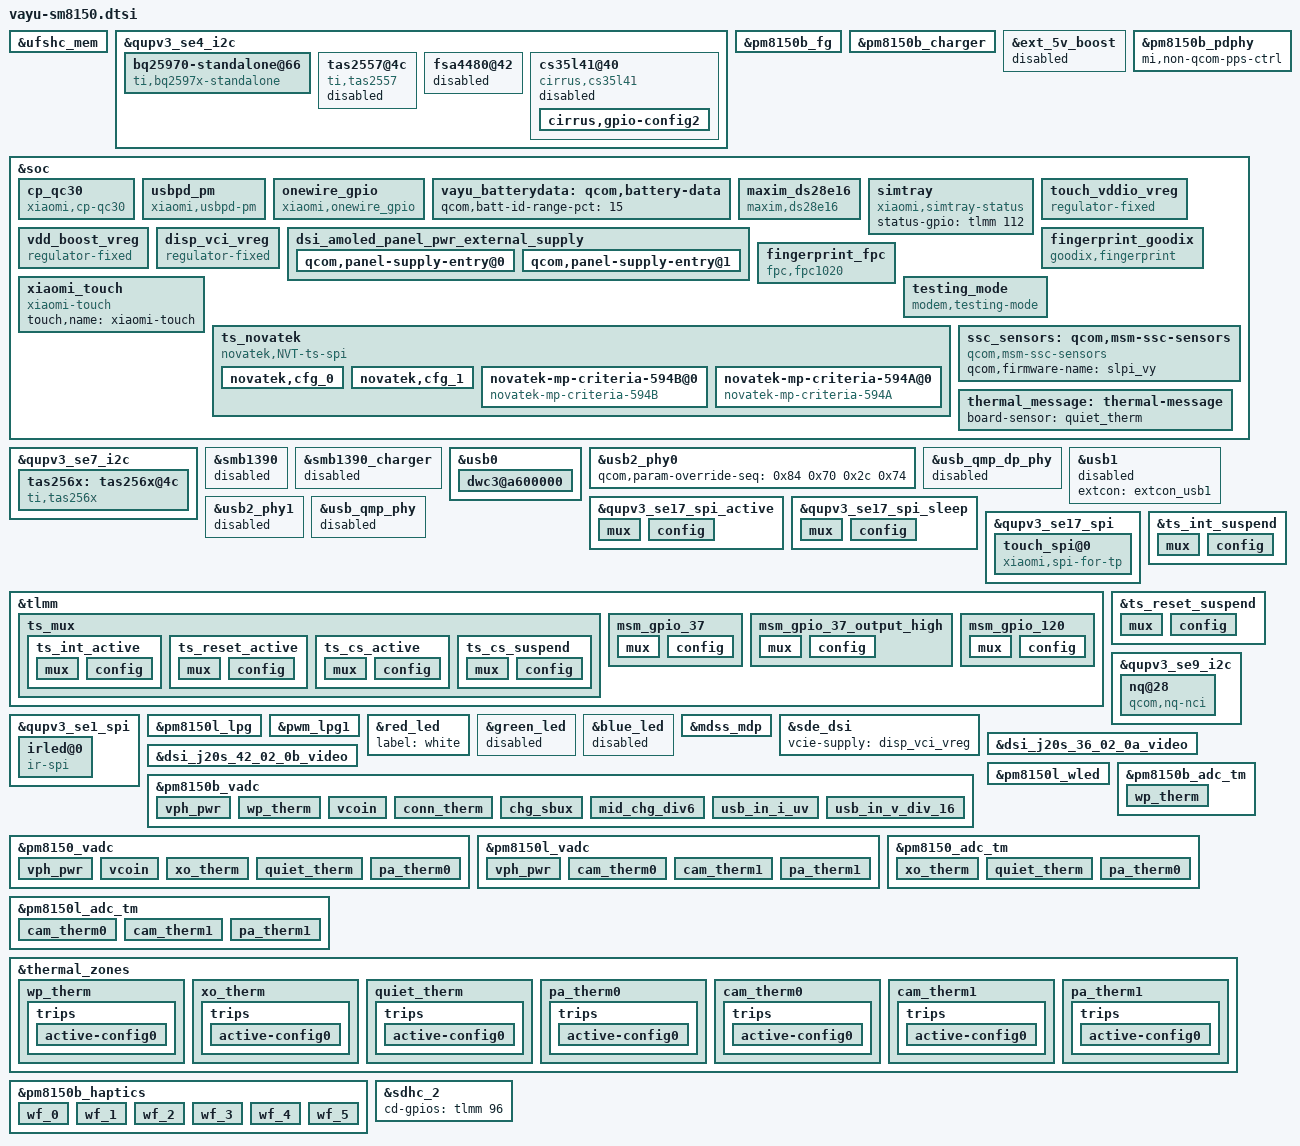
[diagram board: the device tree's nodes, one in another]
/*
this file is for attribution only of vayu
And public attribution of xiaomi platforms(like J20S and so and)
*/
#include "vayu-pinctrl.dtsi"
#include "xiaomi-sm8150-common.dtsi"
#include "vayu-sm8150-camera-sensor-mtp.dtsi"

&ufshc_mem {
	vcc-voltage-level = <2504000 2950000>;
	vcc-low-voltage-sup;
	qcom,vccq-parent-supply = <&pm8150l_s8>;
	qcom,vccq-parent-max-microamp = <210000>;
	vccq-supply = <&pm8150_l9>;
	vccq-max-microamp = <700000>;
};

&qupv3_se4_i2c {
#include "smb1390.dtsi"
};



&pm8150b_fg {
	qcom,battery-data = <&vayu_batterydata>;
	qcom,rapid-soc-dec-en;
	qcom,soc-scale-mode-en;
	qcom,five-pin-battery;
	qcom,soc-hi-res;
	qcom,soc_decimal_rate = <
		0  38
		10 35
		20 33
		30 33
		40 33
		50 33
		60 33
		70 30
		80 25
		90 20
		95 10 >;
	qcom,ki-coeff-low-chg = <315>;
	qcom,ki-coeff-med-chg = <183>;
	qcom,fg-sys-term-current = <(-300)>;
	qcom,fg-ffc-sys-term-current = <(-1160)>;
	qcom,fg-cutoff-voltage = <3400>;
	qcom,fg-cutoff-current = <200>;
	qcom,fg-empty-voltage = <3100>;
	qcom,soc-scale-vbatt-mv = <3600>;
	qcom,fg-batt-temp-delta = <6>;
	qcom,fg-force-load-profile;
	qcom,shutdown-delay-enable;
	/* ESR fast calibration */
	qcom,fg-esr-timer-chg-fast = <0 7>;
	qcom,fg-esr-timer-dischg-fast = <0 7>;
	qcom,fg-esr-timer-chg-slow = <0 96>;
	qcom,fg-esr-timer-dischg-slow = <0 96>;
	qcom,fg-esr-cal-soc-thresh = <26 230>;
	qcom,fg-esr-cal-temp-thresh = <10 40>;
	qcom,ki-coeff-chg-med-hi-thresh-ma = <1000>;
	qcom,ki-coeff-chg-low-med-thresh-ma = <500>;
	qcom,ffc-ki-coeff-chg-med-hi-thresh-ma = <3900>;
	qcom,ffc-ki-coeff-chg-low-med-thresh-ma = <3500>;
};

&pm8150b_charger {
	qcom,sec-charger-config = <0>;
	qcom,usb-icl-ua = <3000000>;
	qcom,fcc-max-ua = <5900000>;
	qcom,fv-max-uv = <4475000>;
	qcom,non-fcc-fv-max-uv = <4450000>;
	//qcom,chg-warm-th= <450>;
	//qcom,chg-cool-th= <150>;
	qcom,auto-recharge-soc = <99>;
	qcom,chg-term-src = <1>;
	qcom,chg-term-current-ma = <(-200)>;
	mi,use-bq-pump;
	qcom,usbpd-phandle = <&pm8150b_pdphy>;
	qcom,battery-data = <&vayu_batterydata>;
	//mi,six-pin-step-chg-params = <4250000  6000000
	//			4450000  5400000
	//			4480000  4000000>;
	//mi,six-pin-step-chg;
	//mi,six-pin-soc-th = <45>;
	mi,fcc-batt-unverify-ua = <2000000>;
	mi,support-ffc;
	qcom,disable-suspend-on-collapse;
	qcom,thermal-mitigation = <3000000 2800000 2600000 2400000 2200000 2100000 2000000
				   1800000 1600000 1500000 1400000 1200000 1000000 900000
				   800000 500000>;
	qcom,thermal-mitigation-icl
				= <2800000 2700000 2600000 2400000 2200000 2100000 2000000
				   2000000 2000000 2000000 2000000 2000000 2000000 2000000
				   2000000 2000000>;
	qcom,thermal-mitigation-dcp
				= <1800000 1800000 1800000 1800000 1800000 1800000 1800000
				   1800000 1800000 1700000 1600000 1400000 1200000 1100000
				   1100000 1000000>;
	qcom,thermal-mitigation-qc2
				= <1500000 1500000 1500000 1500000 1450000 1400000 1350000
				   1300000 1150000 1100000 1000000 900000 850000 750000
				   650000 500000>;
	qcom,thermal-fcc-qc3-normal
				= <3200000 3000000 2800000 2600000 2500000 2400000 2300000
				   2200000 2100000 1800000 1600000 1400000 1200000 1000000
				   750000 750000>;
	qcom,thermal-fcc-qc3-cp
				= <3600000 3600000 3600000 3600000 3200000 3200000 3200000
				   3200000 3100000 2800000 2400000 2200000 2000000 1300000
				   750000 300000>;
	qcom,thermal-fcc-qc3-classb-cp
				= <4800000 4700000 4600000 4500000 4400000 4200000 4200000
				   4200000 4000000 3600000 3400000 3200000 3000000 2200000
				   1000000 300000>;
	qcom,thermal-mitigation-pd-base
				= <3000000 2800000 2600000 2500000 2500000 2500000 2500000
				   2500000 2500000 2400000 2200000 2000000 1600000 1300000
				   1000000 500000>;
	qcom,thermal-fcc-pps-cp
				= <4800000 4700000 4600000 4500000 4400000 4200000 4200000
				   4200000 4000000 3600000 3400000 3200000 3000000 2200000
				   1000000 300000>;
	qcom,thermal-fcc-pps-bq
				= <6000000 5700000 5475000 5250000 5025000 4800000 4575000
				   4350000 4100000 3500000 3000000 2400000 2000000 1500000
				   1000000 500000>;
	qcom,thermal-fcc-qc3-cp
				= <4800000 4600000 4400000 4200000 4000000 3800000 3600000
				   3400000 3000000 2600000 2400000 2200000 2000000 1300000
				   1000000 300000>;
	qcom,thermal-fcc-qc3-classb-cp
				= <5100000 4700000 4300000 4000000 3600000 3500000 3400000
				   3400000 3400000 3200000 2500000 2200000 2000000 1300000
				   1000000 300000>;
	qcom,thermal-mitigation-pd-base
				= <3000000 2800000 2600000 2400000 2200000 2000000 1800000
				   1600000 1600000 1400000 1200000 1100000 1050000 1000000
				   950000 500000>;
	qcom,thermal-mitigation-voice
				= <6000000 2200000 2200000 1000000 1000000 800000  800000
				   800000  800000  700000  700000  600000  600000  600000
				   500000  400000>;


	io-channels = <&pm8150b_vadc ADC_MID_CHG_DIV6>,
		      <&pm8150b_vadc ADC_USB_IN_V_16>,
		      <&pm8150b_vadc ADC_USB_IN_I>,
		      <&pm8150b_vadc ADC_SBUx>,
		      <&pm8150b_vadc ADC_VPH_PWR>,
		      <&pm8150b_vadc ADC_CHG_TEMP>;
	io-channel-names = "mid_voltage",
			   "usb_in_voltage",
			   "usb_in_current",
			   "sbux_res",
			   "vph_voltage",
			   "chg_temp";
//	qcom,battery-data = <&mtp_batterydata>;
	dpdm-supply = <&usb2_phy0>;
	qcom,distinguish-qc-class-ab;
	qcom,lpd-disable;
	qcom,sw-jeita-enable;
	qcom,step-charging-enable;
	qcom,wd-bark-time-secs = <16>;
};

&ext_5v_boost {
	status = "disable";
};

&pm8150b_pdphy {
	mi,non-qcom-pps-ctrl;
};

&qupv3_se4_i2c {
	#address-cells = <1>;
	#size-cells = <0>;
	status = "ok";
	bq25970-standalone@66 {
		compatible = "ti,bq2597x-standalone";
		reg = <0x66>;
		interrupt-parent = <&tlmm>;
		interrupts = <10 0x2002>;
		pinctrl-names = "default";
		pinctrl-0 = <&bq2597x_master_int_default &bq2597x_master_int_suspend>;

		/*ti,bq2597x,bat-ovp-disable;*/
		ti,bq2597x,bat-ovp-alarm-disable;
		ti,bq2597x,bat-ocp-disable;
		ti,bq2597x,bat-ocp-alarm-disable;
		ti,bq2597x,bat-ucp-alarm-disable;
		ti,bq2597x,bat-ucp-disable;

		/*ti,bq2597x,bus-ovp-alarm-disable;
		ti,bq2597x,bus-ocp-disable;
		ti,bq2597x,bus-ocp-alarm-disable;*/
		ti,bq2597x,bat-therm-disable;
		ti,bq2597x,bus-therm-disable;
		ti,bq2597x,die-therm-disable;

		ti,bq2597x,bat-ovp-threshold = <4550>;
		ti,bq2597x,bat-ovp-alarm-threshold = <4525>;
		//ti,bq2597x,bat-ocp-threshold = <8000>;
		//ti,bq2597x,bat-ocp-alarm-threshold = <7500>;

		ti,bq2597x,bus-ovp-threshold = <12000>;
		ti,bq2597x,bus-ovp-alarm-threshold = <11000>;
		ti,bq2597x,bus-ocp-threshold = <3750>;
		ti,bq2597x,bus-ocp-alarm-threshold = <3500>;

		//ti,bq2597x,bat-ucp-alarm-threshold = <2000>;

		ti,bq2597x,bat-therm-threshold = <0x15>;/*4.1%*/
		ti,bq2597x,bus-therm-threshold = <0x15>;/*4.1%*/
		ti,bq2597x,die-therm-threshold = <145>;

		ti,bq2597x,ac-ovp-threshold = <14>;
		//ti,bq2597x,sense-resistor-mohm = <2>;

	};
};

&soc {
	cp_qc30 {
		compatible = "xiaomi,cp-qc30";
		status = "ok";
		mi,qc3-bat-volt-max = <4420>;
		mi,qc3-bat-curr-max = <3600>;
		mi,qc3-bus-volt-max = <12000>;
		mi,qc3-bus-curr-max = <2100>;
		mi,qc3-battery-warm-th = <450>;
		mi,use-qcom-gauge;
		//mi,cp-sec-enable;
	};

	usbpd_pm {
		compatible = "xiaomi,usbpd-pm";
		status = "ok";
		mi,pd-bat-volt-max = <4500>;
		mi,pd-ffc-bat-volt-max = <4480>;
		mi,pd-bat-curr-max = <6000>;
		mi,pd-bus-volt-max = <12000>;
		mi,pd-bus-curr-max = <3000>;
		mi,pd-non-ffc-bat-volt-max = <4450>;
		mi,pd-bus-curr-compensate  = <0>;
		mi,pd-battery-warm-th = <450>;
		mi,use-qcom-gauge;
		//mi,cp-sec-enable;
	};

	onewire_gpio: onewire_gpio {
		compatible = "xiaomi,onewire_gpio";
		label = "xm_onewire";
		xiaomi,version = <1>;
		xiaomi,ow_gpio = <&tlmm 21 0x00>;
		mi,onewire-gpio-cfg-addr = <0x03515000 0x4>;
		xiaomi,gpio_number = <21>;
		pinctrl-names = "onewire_active", "onewire_sleep";
		pinctrl-0 = <&onewire_gpio_active>;
		pinctrl-1 = <&onewire_gpio_sleep>;
		status = "ok";
	};
	vayu_batterydata: qcom,battery-data {
		qcom,batt-id-range-pct = <15>;
		#include "fg-gen4-batterydata-vayu-NVT-5160mah.dtsi"
		#include "fg-gen4-batterydata-vayu-sunwoda-5160mah.dtsi"
	};

	maxim_ds28e16: maxim_ds28e16 {
		compatible = "maxim,ds28e16";
		label = "max_ds28e16";
		maxim,version = <1>;
		status = "ok";
	};

        simtray {
                compatible = "xiaomi,simtray-status";
                status-gpio = <&tlmm 112 0x00>;
        };
};

&qupv3_se4_i2c {
	status = "ok";
	tas2557@4c {
		status = "disabled";
		compatible = "ti,tas2557";
		reg = <0x4c>;
		//ti,cdc-reset-gpio = <&tlmm 59 0>;
		ti,irq-gpio = <&tlmm 60 0>;
		ti,i2s-bits = <16>;
		ti,bypass-tmax = <0>;
	};

	fsa4480@42 {
		status = "disabled";
	};

	cs35l41@40 {
		status = "disabled";
		#sound-dai-cells = <1>;
		compatible = "cirrus,cs35l41";
		cs,cdc-reset-gpio = <&tlmm 89 0x01>;
		reg = <0x40>;
		pinctrl-names = "cs35l41_irq_default";
		pinctrl-0 = <&cs35l41_int_default>;
		interrupt-parent = <&tlmm>;
		interrupts = <10 8>;

		cirrus,temp-warn_threshold = <3>;
		cirrus,boost-peak-milliamp = <4000>;
		cirrus,boost-ind-nanohenry = <1000>;
		cirrus,boost-cap-microfarad = <15>;
		cirrus,gpio-config2 {
			cirrus,gpio-src-select = <0x4>;
			cirrus,gpio-output-enable;
		};
/*
		VA-supply = <&dummy_vreg>;
		VP-supply = <&dummy_vreg>;
		interrupt-parent = <&tlmm>;
		interrupts = <11 8>;
		reset-gpios = <&tlmm 7 0x01>;
		VA-supply = <&pm8998_s4>;
		VP-supply = <&audio_vsys>;
		cirrus,boost-peak-milliamp = <4500>;
		cirrus,boost-ind-nanohenry = <1000>;
		cirrus,boost-cap-microfarad = <15>;
		cirrus,gpio-config2 {
			cirrus,gpio-src-select = <0x4>;
			cirrus,gpio-output-enable;
		};
*/
	};
};

&qupv3_se7_i2c {
	status = "ok";
	tas256x:tas256x@4c {
		#sound-dai-cells = <0>;
		compatible = "ti,tas256x";/*or "ti,tas2564" or "ti,tas256x" */
		reg = <0x4c>;//register tas256x_i2c_driver
		ti,left-channel = <0x4d>;  //receiver address
		ti,right-channel = <0x4c>; //speaker address
		ti,channels = <2>; /* channel number */
		ti,reset-gpio = <&tlmm 89 0>;  //SPKR_RST1
		ti,reset-gpio2 = <&tlmm 92 0>;  //SPKR_RST2
		pinctrl-names = "default";
		//pinctrl-0 = <&reset_stat_default>;
		//ti,reset-gpio = <&pm6150l_gpios 8 GPIO_ACTIVE_LOW>;
		ti,irq-gpio = <&tlmm 90 0>;//spkr_int1 left
		ti,irq-gpio2 = <&tlmm 91 0>;//spkr_int2 right
		status = "ok";
		ti,iv-width = <16>;
		ti,vbat-mon = <0>;
	};
};

&smb1390 {
	status = "disabled";
};

&smb1390_charger {
	status = "disabled";
};

&usb0 {
	dwc3@a600000 {
		usb-phy = <&usb2_phy0>, <&usb_nop_phy>;
		maximum-speed = "high-speed";
	};
};

&usb2_phy0 {
	qcom,param-override-seq =
		<0x84 0x70
		 0x2c 0x74>;
};

&usb_qmp_dp_phy {
	status = "disabled";
};

&usb1 {
	extcon = <&extcon_usb1>;
        status = "disabled";
};

&usb2_phy1 {
        status = "disabled";
};

&usb_qmp_phy {
        status = "disabled";
};

&soc {
	touch_vddio_vreg: touch_vddio_vreg {
		compatible = "regulator-fixed";
		regulator-name = "disp_vddio_vreg";
		startup-delay-us = <4000>;
		enable-active-high;
		regulator-boot-on;
		gpio = <&tlmm 100 0>;
	 };

	vdd_boost_vreg: vdd_boost_vreg {
		compatible = "regulator-fixed";
		regulator-name = "vdd_boost_vreg";
		startup-delay-us = <4000>;
		enable-active-high;
		regulator-always-on;
		gpio = <&pm8150b_gpios 5 0>;
	 };

	disp_vci_vreg: disp_vci_vreg {
		compatible = "regulator-fixed";
		regulator-name = "disp_vci_vreg";
		start-delay-us = <4000>;
		enable-active-high;
		regulator-boot-on;
		gpio = <&tlmm 21 0>;
	};

	dsi_amoled_panel_pwr_external_supply: dsi_amoled_panel_pwr_external_supply {
		#address-cells = <1>;
		#size-cells = <0>;

		qcom,panel-supply-entry@0 {
			reg = <0>;
			qcom,supply-name = "vddio";
			qcom,supply-min-voltage = <1800000>;
			qcom,supply-max-voltage = <1800000>;
			qcom,supply-enable-load = <62000>;
			qcom,supply-disable-load = <80>;
			//qcom,supply-post-on-sleep = <20>;
		};

		qcom,panel-supply-entry@1 {
			reg = <1>;
			qcom,supply-name = "vcie";
			qcom,supply-min-voltage = <3000000>;
			qcom,supply-max-voltage = <3000000>;
			qcom,supply-enable-load = <62000>;
			qcom,supply-disable-load = <80>;
			qcom,supply-post-on-sleep = <10>;
			qcom,supply-pre-off-sleep = <10>;
		};
	};

	fingerprint_goodix {
		compatible = "goodix,fingerprint";
		goodix,gpio-reset = <&tlmm 37 0x0>;
		goodix,gpio-irq = <&tlmm 120 0x0>;
		//goodix.gpio_pwr = <&tlmm 125 0x0>;
		//fp_vdd_vreg = <&pm8150l_l7>;
		status = "ok";
	};


        fingerprint_fpc {
               compatible = "fpc,fpc1020";
               fpc,gpio_rst    = <&tlmm 37 0x0>;
               fpc,gpio_irq    = <&tlmm 120 0x0>;
               pinctrl-names = "fpc1020_reset_reset",
                       "fpc1020_reset_active",
                       "fpc1020_irq_active";

               pinctrl-0 = <&msm_gpio_37>;
               pinctrl-1 = <&msm_gpio_37_output_high>;
               pinctrl-2 = <&msm_gpio_120>;
               status = "ok";
       };


	xiaomi_touch {
		compatible = "xiaomi-touch";
		status = "ok";
		touch,name = "xiaomi-touch";
	};

	testing_mode {
		compatible = "modem,testing-mode";
		status-gpio = <&tlmm 81 0x00>,
                      <&tlmm 133 0x00>;
		debounce-time = <30>;
		pinctrl-names = "default";
		pinctrl-0 = <&ant_sub_ctrl_irq &ant_top_ctrl_irq>;
	};
};

/*Touch SPI state init*/
&qupv3_se17_spi_active {
		mux {
				pins = "gpio55", "gpio56", "gpio57";
				function = "qup17";
		};

		config {
				pins = "gpio55", "gpio56", "gpio57";
				drive-strength = <6>;
				// bias-disable;
				bias-pull-down;
		};
};

&qupv3_se17_spi_sleep {
		mux {
				pins = "gpio55", "gpio56", "gpio57";
				function = "gpio";
		};

		config {
				pins = "gpio55", "gpio56", "gpio57";
				drive-strength = <6>;
				bias-pull-down;
		};
};

&qupv3_se17_spi {
		pinctrl-0 = <&qupv3_se17_spi_active>;
		pinctrl-1 = <&qupv3_se17_spi_sleep>;
};

/*IC int pin, rst pin init*/
&tlmm {
	ts_mux {
		ts_int_active: ts_int_active {
			mux {
				pins = "gpio122";
				function = "gpio";
			};

			config {
				pins = "gpio122";
				drive-strength = <16>;
				bias-pull-down;
			};
		};

		ts_reset_active: ts_reset_active {
			mux {
				pins = "gpio12";
				function = "gpio";
			};

			config {
				pins = "gpio12";
				drive-strength = <16>;
				bias-pull-up;
			};
		};

		ts_cs_active: ts_cs_active {
			mux {
				pins = "gpio58";
				function = "qup17";
			};

			config {
				pins = "gpio58";
				drive-strength = <6>;
				bias-disable;
			};
		};

		ts_cs_suspend: ts_cs_suspend {
			mux {
				pins = "gpio58";
				function = "gpio";
			};

			config {
				pins = "gpio58";
				drive-strength = <6>;
				bias-pull-down;
				output-low;
			};
		};
	};
};

&ts_int_suspend {
		mux {
				pins = "gpio122";
				function = "gpio";
		};

		config {
				pins = "gpio122";
				drive-strength = <16>;
			bias-disable;
			input-enable;
		};
};

&ts_reset_suspend {
	mux {
		pins = "gpio12";
		function = "gpio";
	};

	config {
		pins = "gpio12";
		drive-strength = <16>;
		bias-disable;
	};
};

&qupv3_se17_spi {
		status = "ok";
		touch_spi@0 {
				compatible = "xiaomi,spi-for-tp";
				reg = <0>;
				status = "ok";
				spi-max-frequency = <10000000>;  //10M
		};
};

/* Novatek device tree node */
&soc {
	ts_novatek {
		compatible = "novatek,NVT-ts-spi";
		status = "ok";
		spi-max-frequency = <10000000>;  /*4800000,9600000,15000000,19200000 10M*/
		novatek,reset-gpio = <&tlmm 12 0x00>;
		novatek,irq-gpio = <&tlmm 122 0x2001>;
		pinctrl-names = "pmx_ts_active", "pmx_ts_suspend";
		pinctrl-0 = <&ts_int_active &ts_reset_active &ts_cs_active>;
		pinctrl-1 = <&ts_int_suspend &ts_reset_suspend &ts_cs_suspend>;
		/* 672 */
		/*novatek,swrst-n8-addr = <0x01F01A>;*/
		/* 672A */
		novatek,swrst-n8-addr = <0x03F0FE>;
		novatek,spi-rd-fast-addr = <0x03F310>;
		/* MP */
		novatek,mp-support-dt;
		novatek,config-array-size = <2>;
		novatek,cfg_0 {
			novatek,tp-vendor = <0x46>;
			novatek,display-maker = <0x36>;
			novatek,fw-name = "j20s_novatek_ts_fw01.bin";
			novatek,mp-name = "j20s_novatek_ts_mp01.bin";
			novatek,clicknum-file-name = "nvt+tianma";
		};
		novatek,cfg_1 {
			novatek,tp-vendor = <0x53>;
			novatek,display-maker = <0x42>;
			novatek,fw-name = "j20s_novatek_ts_fw02.bin";
			novatek,mp-name = "j20s_novatek_ts_mp02.bin";
			novatek,clicknum-file-name = "nvt+csot";
		};
		/* for Xiaomi J20S 672C CSOT6.67" module */
		novatek-mp-criteria-594B@0 {
			#address-cells = <1>;
			#size-cells = <0>;
			compatible = "novatek-mp-criteria-594B";
			/* MP Config */
			IC_X_CFG_SIZE = <18>;
			IC_Y_CFG_SIZE = <36>;
			IC_KEY_CFG_SIZE = <4>;
			X_Channel = <18>;
			Y_Channel = <36>;
			AIN_X = <0 1 2 3 4 5 6 7 8 9 10 11 12 13 14 15 16 17>;
			AIN_Y = <0 1 2 3 4 5 6 7 8 9 10 11 12 13 14 15 16 17
						18 19 20 21 22 23 24 25 26 27 28 29 30 31 32 33 34 35>;
			AIN_KEY = <0 1 2 0xFF>;
			/* MP Criteria */
			PS_Config_Lmt_Short_Rawdata_P = <
				14008 14008 14008 14008 14008 14008 14008 14008 14008 14008 14008 14008 14008 14008 14008 14008 14008 14008
				14008 14008 14008 14008 14008 14008 14008 14008 14008 14008 14008 14008 14008 14008 14008 14008 14008 14008
				14008 14008 14008 14008 14008 14008 14008 14008 14008 14008 14008 14008 14008 14008 14008 14008 14008 14008
				14008 14008 14008 14008 14008 14008 14008 14008 14008 14008 14008 14008 14008 14008 14008 14008 14008 14008
				14008 14008 14008 14008 14008 14008 14008 14008 14008 14008 14008 14008 14008 14008 14008 14008 14008 14008
				14008 14008 14008 14008 14008 14008 14008 14008 14008 14008 14008 14008 14008 14008 14008 14008 14008 14008
				14008 14008 14008 14008 14008 14008 14008 14008 14008 14008 14008 14008 14008 14008 14008 14008 14008 14008
				14008 14008 14008 14008 14008 14008 14008 14008 14008 14008 14008 14008 14008 14008 14008 14008 14008 14008
				14008 14008 14008 14008 14008 14008 14008 14008 14008 14008 14008 14008 14008 14008 14008 14008 14008 14008
				14008 14008 14008 14008 14008 14008 14008 14008 14008 14008 14008 14008 14008 14008 14008 14008 14008 14008
				14008 14008 14008 14008 14008 14008 14008 14008 14008 14008 14008 14008 14008 14008 14008 14008 14008 14008
				14008 14008 14008 14008 14008 14008 14008 14008 14008 14008 14008 14008 14008 14008 14008 14008 14008 14008
				14008 14008 14008 14008 14008 14008 14008 14008 14008 14008 14008 14008 14008 14008 14008 14008 14008 14008
				14008 14008 14008 14008 14008 14008 14008 14008 14008 14008 14008 14008 14008 14008 14008 14008 14008 14008
				14008 14008 14008 14008 14008 14008 14008 14008 14008 14008 14008 14008 14008 14008 14008 14008 14008 14008
				14008 14008 14008 14008 14008 14008 14008 14008 14008 14008 14008 14008 14008 14008 14008 14008 14008 14008
				14008 14008 14008 14008 14008 14008 14008 14008 14008 14008 14008 14008 14008 14008 14008 14008 14008 14008
				14008 14008 14008 14008 14008 14008 14008 14008 14008 14008 14008 14008 14008 14008 14008 14008 14008 14008
				14008 14008 14008 14008 14008 14008 14008 14008 14008 14008 14008 14008 14008 14008 14008 14008 14008 14008
				14008 14008 14008 14008 14008 14008 14008 14008 14008 14008 14008 14008 14008 14008 14008 14008 14008 14008
				14008 14008 14008 14008 14008 14008 14008 14008 14008 14008 14008 14008 14008 14008 14008 14008 14008 14008
				14008 14008 14008 14008 14008 14008 14008 14008 14008 14008 14008 14008 14008 14008 14008 14008 14008 14008
				14008 14008 14008 14008 14008 14008 14008 14008 14008 14008 14008 14008 14008 14008 14008 14008 14008 14008
				14008 14008 14008 14008 14008 14008 14008 14008 14008 14008 14008 14008 14008 14008 14008 14008 14008 14008
				14008 14008 14008 14008 14008 14008 14008 14008 14008 14008 14008 14008 14008 14008 14008 14008 14008 14008
				14008 14008 14008 14008 14008 14008 14008 14008 14008 14008 14008 14008 14008 14008 14008 14008 14008 14008
				14008 14008 14008 14008 14008 14008 14008 14008 14008 14008 14008 14008 14008 14008 14008 14008 14008 14008
				14008 14008 14008 14008 14008 14008 14008 14008 14008 14008 14008 14008 14008 14008 14008 14008 14008 14008
				14008 14008 14008 14008 14008 14008 14008 14008 14008 14008 14008 14008 14008 14008 14008 14008 14008 14008
				14008 14008 14008 14008 14008 14008 14008 14008 14008 14008 14008 14008 14008 14008 14008 14008 14008 14008
				14008 14008 14008 14008 14008 14008 14008 14008 14008 14008 14008 14008 14008 14008 14008 14008 14008 14008
				14008 14008 14008 14008 14008 14008 14008 14008 14008 14008 14008 14008 14008 14008 14008 14008 14008 14008
				14008 14008 14008 14008 14008 14008 14008 14008 14008 14008 14008 14008 14008 14008 14008 14008 14008 14008
				14008 14008 14008 14008 14008 14008 14008 14008 14008 14008 14008 14008 14008 14008 14008 14008 14008 14008
				14008 14008 14008 14008 14008 14008 14008 14008 14008 14008 14008 14008 14008 14008 14008 14008 14008 14008
				14008 14008 14008 14008 14008 14008 14008 14008 14008 14008 14008 14008 14008 14008 14008 14008 14008 14008
				14008 14008 14008>;

			PS_Config_Lmt_Short_Rawdata_N = <
				10000 10000 10000 10000 10000 10000 10000 10000 10000 10000 10000 10000 10000 10000 10000 10000 10000 10000
				10000 10000 10000 10000 10000 10000 10000 10000 10000 10000 10000 10000 10000 10000 10000 10000 10000 10000
				10000 10000 10000 10000 10000 10000 10000 10000 10000 10000 10000 10000 10000 10000 10000 10000 10000 10000
				10000 10000 10000 10000 10000 10000 10000 10000 10000 10000 10000 10000 10000 10000 10000 10000 10000 10000
				10000 10000 10000 10000 10000 10000 10000 10000 10000 10000 10000 10000 10000 10000 10000 10000 10000 10000
				10000 10000 10000 10000 10000 10000 10000 10000 10000 10000 10000 10000 10000 10000 10000 10000 10000 10000
				10000 10000 10000 10000 10000 10000 10000 10000 10000 10000 10000 10000 10000 10000 10000 10000 10000 10000
				10000 10000 10000 10000 10000 10000 10000 10000 10000 10000 10000 10000 10000 10000 10000 10000 10000 10000
				10000 10000 10000 10000 10000 10000 10000 10000 10000 10000 10000 10000 10000 10000 10000 10000 10000 10000
				10000 10000 10000 10000 10000 10000 10000 10000 10000 10000 10000 10000 10000 10000 10000 10000 10000 10000
				10000 10000 10000 10000 10000 10000 10000 10000 10000 10000 10000 10000 10000 10000 10000 10000 10000 10000
				10000 10000 10000 10000 10000 10000 10000 10000 10000 10000 10000 10000 10000 10000 10000 10000 10000 10000
				10000 10000 10000 10000 10000 10000 10000 10000 10000 10000 10000 10000 10000 10000 10000 10000 10000 10000
				10000 10000 10000 10000 10000 10000 10000 10000 10000 10000 10000 10000 10000 10000 10000 10000 10000 10000
				10000 10000 10000 10000 10000 10000 10000 10000 10000 10000 10000 10000 10000 10000 10000 10000 10000 10000
				10000 10000 10000 10000 10000 10000 10000 10000 10000 10000 10000 10000 10000 10000 10000 10000 10000 10000
				10000 10000 10000 10000 10000 10000 10000 10000 10000 10000 10000 10000 10000 10000 10000 10000 10000 10000
				10000 10000 10000 10000 10000 10000 10000 10000 10000 10000 10000 10000 10000 10000 10000 10000 10000 10000
				10000 10000 10000 10000 10000 10000 10000 10000 10000 10000 10000 10000 10000 10000 10000 10000 10000 10000
				10000 10000 10000 10000 10000 10000 10000 10000 10000 10000 10000 10000 10000 10000 10000 10000 10000 10000
				10000 10000 10000 10000 10000 10000 10000 10000 10000 10000 10000 10000 10000 10000 10000 10000 10000 10000
				10000 10000 10000 10000 10000 10000 10000 10000 10000 10000 10000 10000 10000 10000 10000 10000 10000 10000
				10000 10000 10000 10000 10000 10000 10000 10000 10000 10000 10000 10000 10000 10000 10000 10000 10000 10000
				10000 10000 10000 10000 10000 10000 10000 10000 10000 10000 10000 10000 10000 10000 10000 10000 10000 10000
				10000 10000 10000 10000 10000 10000 10000 10000 10000 10000 10000 10000 10000 10000 10000 10000 10000 10000
				10000 10000 10000 10000 10000 10000 10000 10000 10000 10000 10000 10000 10000 10000 10000 10000 10000 10000
				10000 10000 10000 10000 10000 10000 10000 10000 10000 10000 10000 10000 10000 10000 10000 10000 10000 10000
				10000 10000 10000 10000 10000 10000 10000 10000 10000 10000 10000 10000 10000 10000 10000 10000 10000 10000
				10000 10000 10000 10000 10000 10000 10000 10000 10000 10000 10000 10000 10000 10000 10000 10000 10000 10000
				10000 10000 10000 10000 10000 10000 10000 10000 10000 10000 10000 10000 10000 10000 10000 10000 10000 10000
				10000 10000 10000 10000 10000 10000 10000 10000 10000 10000 10000 10000 10000 10000 10000 10000 10000 10000
				10000 10000 10000 10000 10000 10000 10000 10000 10000 10000 10000 10000 10000 10000 10000 10000 10000 10000
				10000 10000 10000 10000 10000 10000 10000 10000 10000 10000 10000 10000 10000 10000 10000 10000 10000 10000
				10000 10000 10000 10000 10000 10000 10000 10000 10000 10000 10000 10000 10000 10000 10000 10000 10000 10000
				10000 10000 10000 10000 10000 10000 10000 10000 10000 10000 10000 10000 10000 10000 10000 10000 10000 10000
				10000 10000 10000 10000 10000 10000 10000 10000 10000 10000 10000 10000 10000 10000 10000 10000 10000 10000
				10000 10000 10000>;

			PS_Config_Lmt_Open_Rawdata_P = <
				5120 5120 5120 5120 5120 5120 5120 5120 5120 5120 5120 5120 5120 5120 5120 5120 5120 5120
				5120 5120 5120 5120 5120 5120 5120 5120 5120 5120 5120 5120 5120 5120 5120 5120 5120 5120
				5120 5120 5120 5120 5120 5120 5120 5120 5120 5120 5120 5120 5120 5120 5120 5120 5120 5120
				5120 5120 5120 5120 5120 5120 5120 5120 5120 5120 5120 5120 5120 5120 5120 5120 5120 5120
				5120 5120 5120 5120 5120 5120 5120 5120 5120 5120 5120 5120 5120 5120 5120 5120 5120 5120
				5120 5120 5120 5120 5120 5120 5120 5120 5120 5120 5120 5120 5120 5120 5120 5120 5120 5120
				5120 5120 5120 5120 5120 5120 5120 5120 5120 5120 5120 5120 5120 5120 5120 5120 5120 5120
				5120 5120 5120 5120 5120 5120 5120 5120 5120 5120 5120 5120 5120 5120 5120 5120 5120 5120
				5120 5120 5120 5120 5120 5120 5120 5120 5120 5120 5120 5120 5120 5120 5120 5120 5120 5120
				5120 5120 5120 5120 5120 5120 5120 5120 5120 5120 5120 5120 5120 5120 5120 5120 5120 5120
				5120 5120 5120 5120 5120 5120 5120 5120 5120 5120 5120 5120 5120 5120 5120 5120 5120 5120
				5120 5120 5120 5120 5120 5120 5120 5120 5120 5120 5120 5120 5120 5120 5120 5120 5120 5120
				5120 5120 5120 5120 5120 5120 5120 5120 5120 5120 5120 5120 5120 5120 5120 5120 5120 5120
				5120 5120 5120 5120 5120 5120 5120 5120 5120 5120 5120 5120 5120 5120 5120 5120 5120 5120
				5120 5120 5120 5120 5120 5120 5120 5120 5120 5120 5120 5120 5120 5120 5120 5120 5120 5120
				5120 5120 5120 5120 5120 5120 5120 5120 5120 5120 5120 5120 5120 5120 5120 5120 5120 5120
				5120 5120 5120 5120 5120 5120 5120 5120 5120 5120 5120 5120 5120 5120 5120 5120 5120 5120
				5120 5120 5120 5120 5120 5120 5120 5120 5120 5120 5120 5120 5120 5120 5120 5120 5120 5120
				5120 5120 5120 5120 5120 5120 5120 5120 5120 5120 5120 5120 5120 5120 5120 5120 5120 5120
				5120 5120 5120 5120 5120 5120 5120 5120 5120 5120 5120 5120 5120 5120 5120 5120 5120 5120
				5120 5120 5120 5120 5120 5120 5120 5120 5120 5120 5120 5120 5120 5120 5120 5120 5120 5120
				5120 5120 5120 5120 5120 5120 5120 5120 5120 5120 5120 5120 5120 5120 5120 5120 5120 5120
				5120 5120 5120 5120 5120 5120 5120 5120 5120 5120 5120 5120 5120 5120 5120 5120 5120 5120
				5120 5120 5120 5120 5120 5120 5120 5120 5120 5120 5120 5120 5120 5120 5120 5120 5120 5120
				5120 5120 5120 5120 5120 5120 5120 5120 5120 5120 5120 5120 5120 5120 5120 5120 5120 5120
				5120 5120 5120 5120 5120 5120 5120 5120 5120 5120 5120 5120 5120 5120 5120 5120 5120 5120
				5120 5120 5120 5120 5120 5120 5120 5120 5120 5120 5120 5120 5120 5120 5120 5120 5120 5120
				5120 5120 5120 5120 5120 5120 5120 5120 5120 5120 5120 5120 5120 5120 5120 5120 5120 5120
				5120 5120 5120 5120 5120 5120 5120 5120 5120 5120 5120 5120 5120 5120 5120 5120 5120 5120
				5120 5120 5120 5120 5120 5120 5120 5120 5120 5120 5120 5120 5120 5120 5120 5120 5120 5120
				5120 5120 5120 5120 5120 5120 5120 5120 5120 5120 5120 5120 5120 5120 5120 5120 5120 5120
				5120 5120 5120 5120 5120 5120 5120 5120 5120 5120 5120 5120 5120 5120 5120 5120 5120 5120
				5120 5120 5120 5120 5120 5120 5120 5120 5120 5120 5120 5120 5120 5120 5120 5120 5120 5120
				5120 5120 5120 5120 5120 5120 5120 5120 5120 5120 5120 5120 5120 5120 5120 5120 5120 5120
				5120 5120 5120 5120 5120 5120 5120 5120 5120 5120 5120 5120 5120 5120 5120 5120 5120 5120
				5120 5120 5120 5120 5120 5120 5120 5120 5120 5120 5120 5120 5120 5120 5120 5120 5120 5120
				5120 5120 5120>;

			PS_Config_Lmt_Open_Rawdata_N = <
				(-511) (-511) (-511) (-511) (-511) (-511) (-511) (-511) (-511) (-511) (-511) (-511) (-511) (-511) (-511) (-511) (-511) (-511)
				(-511) (-511) (-511) (-511) (-511) (-511) (-511) (-511) (-511) (-511) (-511) (-511) (-511) (-511) (-511) (-511) (-511) (-511)
				(-511) (-511) (-511) (-511) (-511) (-511) (-511) (-511) (-511) (-511) (-511) (-511) (-511) (-511) (-511) (-511) (-511) (-511)
				(-511) (-511) (-511) (-511) (-511) (-511) (-511) (-511) (-511) (-511) (-511) (-511) (-511) (-511) (-511) (-511) (-511) (-511)
				(-511) (-511) (-511) (-511) (-511) (-511) (-511) (-511) (-511) (-511) (-511) (-511) (-511) (-511) (-511) (-511) (-511) (-511)
				(-511) (-511) (-511) (-511) (-511) (-511) (-511) (-511) (-511) (-511) (-511) (-511) (-511) (-511) (-511) (-511) (-511) (-511)
				(-511) (-511) (-511) (-511) (-511) (-511) (-511) (-511) (-511) (-511) (-511) (-511) (-511) (-511) (-511) (-511) (-511) (-511)
				(-511) (-511) (-511) (-511) (-511) (-511) (-511) (-511) (-511) (-511) (-511) (-511) (-511) (-511) (-511) (-511) (-511) (-511)
				(-511) (-511) (-511) (-511) (-511) (-511) (-511) (-511) (-511) (-511) (-511) (-511) (-511) (-511) (-511) (-511) (-511) (-511)
				(-511) (-511) (-511) (-511) (-511) (-511) (-511) (-511) (-511) (-511) (-511) (-511) (-511) (-511) (-511) (-511) (-511) (-511)
				(-511) (-511) (-511) (-511) (-511) (-511) (-511) (-511) (-511) (-511) (-511) (-511) (-511) (-511) (-511) (-511) (-511) (-511)
				(-511) (-511) (-511) (-511) (-511) (-511) (-511) (-511) (-511) (-511) (-511) (-511) (-511) (-511) (-511) (-511) (-511) (-511)
				(-511) (-511) (-511) (-511) (-511) (-511) (-511) (-511) (-511) (-511) (-511) (-511) (-511) (-511) (-511) (-511) (-511) (-511)
				(-511) (-511) (-511) (-511) (-511) (-511) (-511) (-511) (-511) (-511) (-511) (-511) (-511) (-511) (-511) (-511) (-511) (-511)
				(-511) (-511) (-511) (-511) (-511) (-511) (-511) (-511) (-511) (-511) (-511) (-511) (-511) (-511) (-511) (-511) (-511) (-511)
				(-511) (-511) (-511) (-511) (-511) (-511) (-511) (-511) (-511) (-511) (-511) (-511) (-511) (-511) (-511) (-511) (-511) (-511)
				(-511) (-511) (-511) (-511) (-511) (-511) (-511) (-511) (-511) (-511) (-511) (-511) (-511) (-511) (-511) (-511) (-511) (-511)
				(-511) (-511) (-511) (-511) (-511) (-511) (-511) (-511) (-511) (-511) (-511) (-511) (-511) (-511) (-511) (-511) (-511) (-511)
				(-511) (-511) (-511) (-511) (-511) (-511) (-511) (-511) (-511) (-511) (-511) (-511) (-511) (-511) (-511) (-511) (-511) (-511)
				(-511) (-511) (-511) (-511) (-511) (-511) (-511) (-511) (-511) (-511) (-511) (-511) (-511) (-511) (-511) (-511) (-511) (-511)
				(-511) (-511) (-511) (-511) (-511) (-511) (-511) (-511) (-511) (-511) (-511) (-511) (-511) (-511) (-511) (-511) (-511) (-511)
				(-511) (-511) (-511) (-511) (-511) (-511) (-511) (-511) (-511) (-511) (-511) (-511) (-511) (-511) (-511) (-511) (-511) (-511)
				(-511) (-511) (-511) (-511) (-511) (-511) (-511) (-511) (-511) (-511) (-511) (-511) (-511) (-511) (-511) (-511) (-511) (-511)
				(-511) (-511) (-511) (-511) (-511) (-511) (-511) (-511) (-511) (-511) (-511) (-511) (-511) (-511) (-511) (-511) (-511) (-511)
				(-511) (-511) (-511) (-511) (-511) (-511) (-511) (-511) (-511) (-511) (-511) (-511) (-511) (-511) (-511) (-511) (-511) (-511)
				(-511) (-511) (-511) (-511) (-511) (-511) (-511) (-511) (-511) (-511) (-511) (-511) (-511) (-511) (-511) (-511) (-511) (-511)
				(-511) (-511) (-511) (-511) (-511) (-511) (-511) (-511) (-511) (-511) (-511) (-511) (-511) (-511) (-511) (-511) (-511) (-511)
				(-511) (-511) (-511) (-511) (-511) (-511) (-511) (-511) (-511) (-511) (-511) (-511) (-511) (-511) (-511) (-511) (-511) (-511)
				(-511) (-511) (-511) (-511) (-511) (-511) (-511) (-511) (-511) (-511) (-511) (-511) (-511) (-511) (-511) (-511) (-511) (-511)
				(-511) (-511) (-511) (-511) (-511) (-511) (-511) (-511) (-511) (-511) (-511) (-511) (-511) (-511) (-511) (-511) (-511) (-511)
				(-511) (-511) (-511) (-511) (-511) (-511) (-511) (-511) (-511) (-511) (-511) (-511) (-511) (-511) (-511) (-511) (-511) (-511)
				(-511) (-511) (-511) (-511) (-511) (-511) (-511) (-511) (-511) (-511) (-511) (-511) (-511) (-511) (-511) (-511) (-511) (-511)
				(-511) (-511) (-511) (-511) (-511) (-511) (-511) (-511) (-511) (-511) (-511) (-511) (-511) (-511) (-511) (-511) (-511) (-511)
				(-511) (-511) (-511) (-511) (-511) (-511) (-511) (-511) (-511) (-511) (-511) (-511) (-511) (-511) (-511) (-511) (-511) (-511)
				(-511) (-511) (-511) (-511) (-511) (-511) (-511) (-511) (-511) (-511) (-511) (-511) (-511) (-511) (-511) (-511) (-511) (-511)
				(-511) (-511) (-511) (-511) (-511) (-511) (-511) (-511) (-511) (-511) (-511) (-511) (-511) (-511) (-511) (-511) (-511) (-511)
				(-511) (-511) (-511)>;

			PS_Config_Lmt_FW_Rawdata_P = <
				3840 3840 3840 3840 3840 3840 3840 3840 3840 3840 3840 3840 3840 3840 3840 3840 3840 3840
				3840 3840 3840 3840 3840 3840 3840 3840 3840 3840 3840 3840 3840 3840 3840 3840 3840 3840
				3840 3840 3840 3840 3840 3840 3840 3840 3840 3840 3840 3840 3840 3840 3840 3840 3840 3840
				3840 3840 3840 3840 3840 3840 3840 3840 3840 3840 3840 3840 3840 3840 3840 3840 3840 3840
				3840 3840 3840 3840 3840 3840 3840 3840 3840 3840 3840 3840 3840 3840 3840 3840 3840 3840
				3840 3840 3840 3840 3840 3840 3840 3840 3840 3840 3840 3840 3840 3840 3840 3840 3840 3840
				3840 3840 3840 3840 3840 3840 3840 3840 3840 3840 3840 3840 3840 3840 3840 3840 3840 3840
				3840 3840 3840 3840 3840 3840 3840 3840 3840 3840 3840 3840 3840 3840 3840 3840 3840 3840
				3840 3840 3840 3840 3840 3840 3840 3840 3840 3840 3840 3840 3840 3840 3840 3840 3840 3840
				3840 3840 3840 3840 3840 3840 3840 3840 3840 3840 3840 3840 3840 3840 3840 3840 3840 3840
				3840 3840 3840 3840 3840 3840 3840 3840 3840 3840 3840 3840 3840 3840 3840 3840 3840 3840
				3840 3840 3840 3840 3840 3840 3840 3840 3840 3840 3840 3840 3840 3840 3840 3840 3840 3840
				3840 3840 3840 3840 3840 3840 3840 3840 3840 3840 3840 3840 3840 3840 3840 3840 3840 3840
				3840 3840 3840 3840 3840 3840 3840 3840 3840 3840 3840 3840 3840 3840 3840 3840 3840 3840
				3840 3840 3840 3840 3840 3840 3840 3840 3840 3840 3840 3840 3840 3840 3840 3840 3840 3840
				3840 3840 3840 3840 3840 3840 3840 3840 3840 3840 3840 3840 3840 3840 3840 3840 3840 3840
				3840 3840 3840 3840 3840 3840 3840 3840 3840 3840 3840 3840 3840 3840 3840 3840 3840 3840
				3840 3840 3840 3840 3840 3840 3840 3840 3840 3840 3840 3840 3840 3840 3840 3840 3840 3840
				3840 3840 3840 3840 3840 3840 3840 3840 3840 3840 3840 3840 3840 3840 3840 3840 3840 3840
				3840 3840 3840 3840 3840 3840 3840 3840 3840 3840 3840 3840 3840 3840 3840 3840 3840 3840
				3840 3840 3840 3840 3840 3840 3840 3840 3840 3840 3840 3840 3840 3840 3840 3840 3840 3840
				3840 3840 3840 3840 3840 3840 3840 3840 3840 3840 3840 3840 3840 3840 3840 3840 3840 3840
				3840 3840 3840 3840 3840 3840 3840 3840 3840 3840 3840 3840 3840 3840 3840 3840 3840 3840
				3840 3840 3840 3840 3840 3840 3840 3840 3840 3840 3840 3840 3840 3840 3840 3840 3840 3840
				3840 3840 3840 3840 3840 3840 3840 3840 3840 3840 3840 3840 3840 3840 3840 3840 3840 3840
				3840 3840 3840 3840 3840 3840 3840 3840 3840 3840 3840 3840 3840 3840 3840 3840 3840 3840
				3840 3840 3840 3840 3840 3840 3840 3840 3840 3840 3840 3840 3840 3840 3840 3840 3840 3840
				3840 3840 3840 3840 3840 3840 3840 3840 3840 3840 3840 3840 3840 3840 3840 3840 3840 3840
				3840 3840 3840 3840 3840 3840 3840 3840 3840 3840 3840 3840 3840 3840 3840 3840 3840 3840
				3840 3840 3840 3840 3840 3840 3840 3840 3840 3840 3840 3840 3840 3840 3840 3840 3840 3840
				3840 3840 3840 3840 3840 3840 3840 3840 3840 3840 3840 3840 3840 3840 3840 3840 3840 3840
				3840 3840 3840 3840 3840 3840 3840 3840 3840 3840 3840 3840 3840 3840 3840 3840 3840 3840
				3840 3840 3840 3840 3840 3840 3840 3840 3840 3840 3840 3840 3840 3840 3840 3840 3840 3840
				3840 3840 3840 3840 3840 3840 3840 3840 3840 3840 3840 3840 3840 3840 3840 3840 3840 3840
				3840 3840 3840 3840 3840 3840 3840 3840 3840 3840 3840 3840 3840 3840 3840 3840 3840 3840
				3840 3840 3840 3840 3840 3840 3840 3840 3840 3840 3840 3840 3840 3840 3840 3840 3840 3840
				3840 3840 3840>;

			PS_Config_Lmt_FW_Rawdata_N = <
				240 240 240 240 240 240 240 240 240 240 240 240 240 240 240 240 240 240
				240 240 240 240 240 240 240 240 240 240 240 240 240 240 240 240 240 240
				240 240 240 240 240 240 240 240 240 240 240 240 240 240 240 240 240 240
				240 240 240 240 240 240 240 240 240 240 240 240 240 240 240 240 240 240
				240 240 240 240 240 240 240 240 240 240 240 240 240 240 240 240 240 240
				240 240 240 240 240 240 240 240 240 240 240 240 240 240 240 240 240 240
				240 240 240 240 240 240 240 240 240 240 240 240 240 240 240 240 240 240
				240 240 240 240 240 240 240 240 240 240 240 240 240 240 240 240 240 240
				240 240 240 240 240 240 240 240 240 240 240 240 240 240 240 240 240 240
				240 240 240 240 240 240 240 240 240 240 240 240 240 240 240 240 240 240
				240 240 240 240 240 240 240 240 240 240 240 240 240 240 240 240 240 240
				240 240 240 240 240 240 240 240 240 240 240 240 240 240 240 240 240 240
				240 240 240 240 240 240 240 240 240 240 240 240 240 240 240 240 240 240
				240 240 240 240 240 240 240 240 240 240 240 240 240 240 240 240 240 240
				240 240 240 240 240 240 240 240 240 240 240 240 240 240 240 240 240 240
				240 240 240 240 240 240 240 240 240 240 240 240 240 240 240 240 240 240
				240 240 240 240 240 240 240 240 240 240 240 240 240 240 240 240 240 240
				240 240 240 240 240 240 240 240 240 240 240 240 240 240 240 240 240 240
				240 240 240 240 240 240 240 240 240 240 240 240 240 240 240 240 240 240
				240 240 240 240 240 240 240 240 240 240 240 240 240 240 240 240 240 240
				240 240 240 240 240 240 240 240 240 240 240 240 240 240 240 240 240 240
				240 240 240 240 240 240 240 240 240 240 240 240 240 240 240 240 240 240
				240 240 240 240 240 240 240 240 240 240 240 240 240 240 240 240 240 240
				240 240 240 240 240 240 240 240 240 240 240 240 240 240 240 240 240 240
				240 240 240 240 240 240 240 240 240 240 240 240 240 240 240 240 240 240
				240 240 240 240 240 240 240 240 240 240 240 240 240 240 240 240 240 240
				240 240 240 240 240 240 240 240 240 240 240 240 240 240 240 240 240 240
				240 240 240 240 240 240 240 240 240 240 240 240 240 240 240 240 240 240
				240 240 240 240 240 240 240 240 240 240 240 240 240 240 240 240 240 240
				240 240 240 240 240 240 240 240 240 240 240 240 240 240 240 240 240 240
				240 240 240 240 240 240 240 240 240 240 240 240 240 240 240 240 240 240
				240 240 240 240 240 240 240 240 240 240 240 240 240 240 240 240 240 240
				240 240 240 240 240 240 240 240 240 240 240 240 240 240 240 240 240 240
				240 240 240 240 240 240 240 240 240 240 240 240 240 240 240 240 240 240
				240 240 240 240 240 240 240 240 240 240 240 240 240 240 240 240 240 240
				240 240 240 240 240 240 240 240 240 240 240 240 240 240 240 240 240 240
				240 240 240>;

			PS_Config_Lmt_FW_CC_P = <
				314 314 314 314 314 314 314 314 314 314 314 314 314 314 314 314 314 314
				314 314 314 314 314 314 314 314 314 314 314 314 314 314 314 314 314 314
				314 314 314 314 314 314 314 314 314 314 314 314 314 314 314 314 314 314
				314 314 314 314 314 314 314 314 314 314 314 314 314 314 314 314 314 314
				314 314 314 314 314 314 314 314 314 314 314 314 314 314 314 314 314 314
				314 314 314 314 314 314 314 314 314 314 314 314 314 314 314 314 314 314
				314 314 314 314 314 314 314 314 314 314 314 314 314 314 314 314 314 314
				314 314 314 314 314 314 314 314 314 314 314 314 314 314 314 314 314 314
				314 314 314 314 314 314 314 314 314 314 314 314 314 314 314 314 314 314
				314 314 314 314 314 314 314 314 314 314 314 314 314 314 314 314 314 314
				314 314 314 314 314 314 314 314 314 314 314 314 314 314 314 314 314 314
				314 314 314 314 314 314 314 314 314 314 314 314 314 314 314 314 314 314
				314 314 314 314 314 314 314 314 314 314 314 314 314 314 314 314 314 314
				314 314 314 314 314 314 314 314 314 314 314 314 314 314 314 314 314 314
				314 314 314 314 314 314 314 314 314 314 314 314 314 314 314 314 314 314
				314 314 314 314 314 314 314 314 314 314 314 314 314 314 314 314 314 314
				314 314 314 314 314 314 314 314 314 314 314 314 314 314 314 314 314 314
				314 314 314 314 314 314 314 314 314 314 314 314 314 314 314 314 314 314
				314 314 314 314 314 314 314 314 314 314 314 314 314 314 314 314 314 314
				314 314 314 314 314 314 314 314 314 314 314 314 314 314 314 314 314 314
				314 314 314 314 314 314 314 314 314 314 314 314 314 314 314 314 314 314
				314 314 314 314 314 314 314 314 314 314 314 314 314 314 314 314 314 314
				314 314 314 314 314 314 314 314 314 314 314 314 314 314 314 314 314 314
				314 314 314 314 314 314 314 314 314 314 314 314 314 314 314 314 314 314
				314 314 314 314 314 314 314 314 314 314 314 314 314 314 314 314 314 314
				314 314 314 314 314 314 314 314 314 314 314 314 314 314 314 314 314 314
				314 314 314 314 314 314 314 314 314 314 314 314 314 314 314 314 314 314
				314 314 314 314 314 314 314 314 314 314 314 314 314 314 314 314 314 314
				314 314 314 314 314 314 314 314 314 314 314 314 314 314 314 314 314 314
				314 314 314 314 314 314 314 314 314 314 314 314 314 314 314 314 314 314
				314 314 314 314 314 314 314 314 314 314 314 314 314 314 314 314 314 314
				314 314 314 314 314 314 314 314 314 314 314 314 314 314 314 314 314 314
				314 314 314 314 314 314 314 314 314 314 314 314 314 314 314 314 314 314
				314 314 314 314 314 314 314 314 314 314 314 314 314 314 314 314 314 314
				314 314 314 314 314 314 314 314 314 314 314 314 314 314 314 314 314 314
				314 314 314 314 314 314 314 314 314 314 314 314 314 314 314 314 314 314
				314 314 314>;

			PS_Config_Lmt_FW_CC_N = <
				0 0 0 0 0 0 0 0 0 0 0 0 0 0 0 0 0 0
				0 0 0 0 0 0 0 0 0 0 0 0 0 0 0 0 0 0
				0 0 0 0 0 0 0 0 0 0 0 0 0 0 0 0 0 0
				0 0 0 0 0 0 0 0 0 0 0 0 0 0 0 0 0 0
				0 0 0 0 0 0 0 0 0 0 0 0 0 0 0 0 0 0
				0 0 0 0 0 0 0 0 0 0 0 0 0 0 0 0 0 0
				0 0 0 0 0 0 0 0 0 0 0 0 0 0 0 0 0 0
				0 0 0 0 0 0 0 0 0 0 0 0 0 0 0 0 0 0
				0 0 0 0 0 0 0 0 0 0 0 0 0 0 0 0 0 0
				0 0 0 0 0 0 0 0 0 0 0 0 0 0 0 0 0 0
				0 0 0 0 0 0 0 0 0 0 0 0 0 0 0 0 0 0
				0 0 0 0 0 0 0 0 0 0 0 0 0 0 0 0 0 0
				0 0 0 0 0 0 0 0 0 0 0 0 0 0 0 0 0 0
				0 0 0 0 0 0 0 0 0 0 0 0 0 0 0 0 0 0
				0 0 0 0 0 0 0 0 0 0 0 0 0 0 0 0 0 0
				0 0 0 0 0 0 0 0 0 0 0 0 0 0 0 0 0 0
				0 0 0 0 0 0 0 0 0 0 0 0 0 0 0 0 0 0
				0 0 0 0 0 0 0 0 0 0 0 0 0 0 0 0 0 0
				0 0 0 0 0 0 0 0 0 0 0 0 0 0 0 0 0 0
				0 0 0 0 0 0 0 0 0 0 0 0 0 0 0 0 0 0
				0 0 0 0 0 0 0 0 0 0 0 0 0 0 0 0 0 0
				0 0 0 0 0 0 0 0 0 0 0 0 0 0 0 0 0 0
				0 0 0 0 0 0 0 0 0 0 0 0 0 0 0 0 0 0
				0 0 0 0 0 0 0 0 0 0 0 0 0 0 0 0 0 0
				0 0 0 0 0 0 0 0 0 0 0 0 0 0 0 0 0 0
				0 0 0 0 0 0 0 0 0 0 0 0 0 0 0 0 0 0
				0 0 0 0 0 0 0 0 0 0 0 0 0 0 0 0 0 0
				0 0 0 0 0 0 0 0 0 0 0 0 0 0 0 0 0 0
				0 0 0 0 0 0 0 0 0 0 0 0 0 0 0 0 0 0
				0 0 0 0 0 0 0 0 0 0 0 0 0 0 0 0 0 0
				0 0 0 0 0 0 0 0 0 0 0 0 0 0 0 0 0 0
				0 0 0 0 0 0 0 0 0 0 0 0 0 0 0 0 0 0
				0 0 0 0 0 0 0 0 0 0 0 0 0 0 0 0 0 0
				0 0 0 0 0 0 0 0 0 0 0 0 0 0 0 0 0 0
				0 0 0 0 0 0 0 0 0 0 0 0 0 0 0 0 0 0
				0 0 0 0 0 0 0 0 0 0 0 0 0 0 0 0 0 0
				0 0 0>;

			PS_Config_Lmt_FW_Diff_P = <
				75 75 75 75 75 75 75 75 75 75 75 75 75 75 75 75 75 75
				75 75 75 75 75 75 75 75 75 75 75 75 75 75 75 75 75 75
				75 75 75 75 75 75 75 75 75 75 75 75 75 75 75 75 75 75
				75 75 75 75 75 75 75 75 75 75 75 75 75 75 75 75 75 75
				75 75 75 75 75 75 75 75 75 75 75 75 75 75 75 75 75 75
				75 75 75 75 75 75 75 75 75 75 75 75 75 75 75 75 75 75
				75 75 75 75 75 75 75 75 75 75 75 75 75 75 75 75 75 75
				75 75 75 75 75 75 75 75 75 75 75 75 75 75 75 75 75 75
				75 75 75 75 75 75 75 75 75 75 75 75 75 75 75 75 75 75
				75 75 75 75 75 75 75 75 75 75 75 75 75 75 75 75 75 75
				75 75 75 75 75 75 75 75 75 75 75 75 75 75 75 75 75 75
				75 75 75 75 75 75 75 75 75 75 75 75 75 75 75 75 75 75
				75 75 75 75 75 75 75 75 75 75 75 75 75 75 75 75 75 75
				75 75 75 75 75 75 75 75 75 75 75 75 75 75 75 75 75 75
				75 75 75 75 75 75 75 75 75 75 75 75 75 75 75 75 75 75
				75 75 75 75 75 75 75 75 75 75 75 75 75 75 75 75 75 75
				75 75 75 75 75 75 75 75 75 75 75 75 75 75 75 75 75 75
				75 75 75 75 75 75 75 75 75 75 75 75 75 75 75 75 75 75
				75 75 75 75 75 75 75 75 75 75 75 75 75 75 75 75 75 75
				75 75 75 75 75 75 75 75 75 75 75 75 75 75 75 75 75 75
				75 75 75 75 75 75 75 75 75 75 75 75 75 75 75 75 75 75
				75 75 75 75 75 75 75 75 75 75 75 75 75 75 75 75 75 75
				75 75 75 75 75 75 75 75 75 75 75 75 75 75 75 75 75 75
				75 75 75 75 75 75 75 75 75 75 75 75 75 75 75 75 75 75
				75 75 75 75 75 75 75 75 75 75 75 75 75 75 75 75 75 75
				75 75 75 75 75 75 75 75 75 75 75 75 75 75 75 75 75 75
				75 75 75 75 75 75 75 75 75 75 75 75 75 75 75 75 75 75
				75 75 75 75 75 75 75 75 75 75 75 75 75 75 75 75 75 75
				75 75 75 75 75 75 75 75 75 75 75 75 75 75 75 75 75 75
				75 75 75 75 75 75 75 75 75 75 75 75 75 75 75 75 75 75
				75 75 75 75 75 75 75 75 75 75 75 75 75 75 75 75 75 75
				75 75 75 75 75 75 75 75 75 75 75 75 75 75 75 75 75 75
				75 75 75 75 75 75 75 75 75 75 75 75 75 75 75 75 75 75
				75 75 75 75 75 75 75 75 75 75 75 75 75 75 75 75 75 75
				75 75 75 75 75 75 75 75 75 75 75 75 75 75 75 75 75 75
				75 75 75 75 75 75 75 75 75 75 75 75 75 75 75 75 75 75
				75 75 75>;

			PS_Config_Lmt_FW_Diff_N = <
				(-75) (-75) (-75) (-75) (-75) (-75) (-75) (-75) (-75) (-75) (-75) (-75) (-75) (-75) (-75) (-75) (-75) (-75)
				(-75) (-75) (-75) (-75) (-75) (-75) (-75) (-75) (-75) (-75) (-75) (-75) (-75) (-75) (-75) (-75) (-75) (-75)
				(-75) (-75) (-75) (-75) (-75) (-75) (-75) (-75) (-75) (-75) (-75) (-75) (-75) (-75) (-75) (-75) (-75) (-75)
				(-75) (-75) (-75) (-75) (-75) (-75) (-75) (-75) (-75) (-75) (-75) (-75) (-75) (-75) (-75) (-75) (-75) (-75)
				(-75) (-75) (-75) (-75) (-75) (-75) (-75) (-75) (-75) (-75) (-75) (-75) (-75) (-75) (-75) (-75) (-75) (-75)
				(-75) (-75) (-75) (-75) (-75) (-75) (-75) (-75) (-75) (-75) (-75) (-75) (-75) (-75) (-75) (-75) (-75) (-75)
				(-75) (-75) (-75) (-75) (-75) (-75) (-75) (-75) (-75) (-75) (-75) (-75) (-75) (-75) (-75) (-75) (-75) (-75)
				(-75) (-75) (-75) (-75) (-75) (-75) (-75) (-75) (-75) (-75) (-75) (-75) (-75) (-75) (-75) (-75) (-75) (-75)
				(-75) (-75) (-75) (-75) (-75) (-75) (-75) (-75) (-75) (-75) (-75) (-75) (-75) (-75) (-75) (-75) (-75) (-75)
				(-75) (-75) (-75) (-75) (-75) (-75) (-75) (-75) (-75) (-75) (-75) (-75) (-75) (-75) (-75) (-75) (-75) (-75)
				(-75) (-75) (-75) (-75) (-75) (-75) (-75) (-75) (-75) (-75) (-75) (-75) (-75) (-75) (-75) (-75) (-75) (-75)
				(-75) (-75) (-75) (-75) (-75) (-75) (-75) (-75) (-75) (-75) (-75) (-75) (-75) (-75) (-75) (-75) (-75) (-75)
				(-75) (-75) (-75) (-75) (-75) (-75) (-75) (-75) (-75) (-75) (-75) (-75) (-75) (-75) (-75) (-75) (-75) (-75)
				(-75) (-75) (-75) (-75) (-75) (-75) (-75) (-75) (-75) (-75) (-75) (-75) (-75) (-75) (-75) (-75) (-75) (-75)
				(-75) (-75) (-75) (-75) (-75) (-75) (-75) (-75) (-75) (-75) (-75) (-75) (-75) (-75) (-75) (-75) (-75) (-75)
				(-75) (-75) (-75) (-75) (-75) (-75) (-75) (-75) (-75) (-75) (-75) (-75) (-75) (-75) (-75) (-75) (-75) (-75)
				(-75) (-75) (-75) (-75) (-75) (-75) (-75) (-75) (-75) (-75) (-75) (-75) (-75) (-75) (-75) (-75) (-75) (-75)
				(-75) (-75) (-75) (-75) (-75) (-75) (-75) (-75) (-75) (-75) (-75) (-75) (-75) (-75) (-75) (-75) (-75) (-75)
				(-75) (-75) (-75) (-75) (-75) (-75) (-75) (-75) (-75) (-75) (-75) (-75) (-75) (-75) (-75) (-75) (-75) (-75)
				(-75) (-75) (-75) (-75) (-75) (-75) (-75) (-75) (-75) (-75) (-75) (-75) (-75) (-75) (-75) (-75) (-75) (-75)
				(-75) (-75) (-75) (-75) (-75) (-75) (-75) (-75) (-75) (-75) (-75) (-75) (-75) (-75) (-75) (-75) (-75) (-75)
				(-75) (-75) (-75) (-75) (-75) (-75) (-75) (-75) (-75) (-75) (-75) (-75) (-75) (-75) (-75) (-75) (-75) (-75)
				(-75) (-75) (-75) (-75) (-75) (-75) (-75) (-75) (-75) (-75) (-75) (-75) (-75) (-75) (-75) (-75) (-75) (-75)
				(-75) (-75) (-75) (-75) (-75) (-75) (-75) (-75) (-75) (-75) (-75) (-75) (-75) (-75) (-75) (-75) (-75) (-75)
				(-75) (-75) (-75) (-75) (-75) (-75) (-75) (-75) (-75) (-75) (-75) (-75) (-75) (-75) (-75) (-75) (-75) (-75)
				(-75) (-75) (-75) (-75) (-75) (-75) (-75) (-75) (-75) (-75) (-75) (-75) (-75) (-75) (-75) (-75) (-75) (-75)
				(-75) (-75) (-75) (-75) (-75) (-75) (-75) (-75) (-75) (-75) (-75) (-75) (-75) (-75) (-75) (-75) (-75) (-75)
				(-75) (-75) (-75) (-75) (-75) (-75) (-75) (-75) (-75) (-75) (-75) (-75) (-75) (-75) (-75) (-75) (-75) (-75)
				(-75) (-75) (-75) (-75) (-75) (-75) (-75) (-75) (-75) (-75) (-75) (-75) (-75) (-75) (-75) (-75) (-75) (-75)
				(-75) (-75) (-75) (-75) (-75) (-75) (-75) (-75) (-75) (-75) (-75) (-75) (-75) (-75) (-75) (-75) (-75) (-75)
				(-75) (-75) (-75) (-75) (-75) (-75) (-75) (-75) (-75) (-75) (-75) (-75) (-75) (-75) (-75) (-75) (-75) (-75)
				(-75) (-75) (-75) (-75) (-75) (-75) (-75) (-75) (-75) (-75) (-75) (-75) (-75) (-75) (-75) (-75) (-75) (-75)
				(-75) (-75) (-75) (-75) (-75) (-75) (-75) (-75) (-75) (-75) (-75) (-75) (-75) (-75) (-75) (-75) (-75) (-75)
				(-75) (-75) (-75) (-75) (-75) (-75) (-75) (-75) (-75) (-75) (-75) (-75) (-75) (-75) (-75) (-75) (-75) (-75)
				(-75) (-75) (-75) (-75) (-75) (-75) (-75) (-75) (-75) (-75) (-75) (-75) (-75) (-75) (-75) (-75) (-75) (-75)
				(-75) (-75) (-75) (-75) (-75) (-75) (-75) (-75) (-75) (-75) (-75) (-75) (-75) (-75) (-75) (-75) (-75) (-75)
				(-75) (-75) (-75)>;

			PS_Config_Diff_Test_Frame = <50>;
		};

		/* for Xiaomi J20S 672C TM6.67" module */
		novatek-mp-criteria-594A@0 {
			#address-cells = <1>;
			#size-cells = <0>;
			compatible = "novatek-mp-criteria-594A";

			/* MP Config */
			IC_X_CFG_SIZE = <16>;
			IC_Y_CFG_SIZE = <36>;
			IC_KEY_CFG_SIZE = <4>;
			X_Channel = <16>;
			Y_Channel = <36>;
			AIN_X = <0 1 2 3 4 5 6 7 8 9 10 11 12 13 14 15>;
			AIN_Y = <0 1 2 3 4 5 6 7 8 9 10 11 12 13 14 15 16 17
						18 19 20 21 22 23 24 25 26 27 28 29 30 31 32 33 34 35>;
			AIN_KEY = <0 1 2 0xFF>;

			/* MP Criteria */
			PS_Config_Lmt_Short_Rawdata_P = <
				14008 14008 14008 14008 14008 14008 14008 14008 14008 14008 14008 14008 14008 14008 14008 14008
				14008 14008 14008 14008 14008 14008 14008 14008 14008 14008 14008 14008 14008 14008 14008 14008
				14008 14008 14008 14008 14008 14008 14008 14008 14008 14008 14008 14008 14008 14008 14008 14008
				14008 14008 14008 14008 14008 14008 14008 14008 14008 14008 14008 14008 14008 14008 14008 14008
				14008 14008 14008 14008 14008 14008 14008 14008 14008 14008 14008 14008 14008 14008 14008 14008
				14008 14008 14008 14008 14008 14008 14008 14008 14008 14008 14008 14008 14008 14008 14008 14008
				14008 14008 14008 14008 14008 14008 14008 14008 14008 14008 14008 14008 14008 14008 14008 14008
				14008 14008 14008 14008 14008 14008 14008 14008 14008 14008 14008 14008 14008 14008 14008 14008
				14008 14008 14008 14008 14008 14008 14008 14008 14008 14008 14008 14008 14008 14008 14008 14008
				14008 14008 14008 14008 14008 14008 14008 14008 14008 14008 14008 14008 14008 14008 14008 14008
				14008 14008 14008 14008 14008 14008 14008 14008 14008 14008 14008 14008 14008 14008 14008 14008
				14008 14008 14008 14008 14008 14008 14008 14008 14008 14008 14008 14008 14008 14008 14008 14008
				14008 14008 14008 14008 14008 14008 14008 14008 14008 14008 14008 14008 14008 14008 14008 14008
				14008 14008 14008 14008 14008 14008 14008 14008 14008 14008 14008 14008 14008 14008 14008 14008
				14008 14008 14008 14008 14008 14008 14008 14008 14008 14008 14008 14008 14008 14008 14008 14008
				14008 14008 14008 14008 14008 14008 14008 14008 14008 14008 14008 14008 14008 14008 14008 14008
				14008 14008 14008 14008 14008 14008 14008 14008 14008 14008 14008 14008 14008 14008 14008 14008
				14008 14008 14008 14008 14008 14008 14008 14008 14008 14008 14008 14008 14008 14008 14008 14008
				14008 14008 14008 14008 14008 14008 14008 14008 14008 14008 14008 14008 14008 14008 14008 14008
				14008 14008 14008 14008 14008 14008 14008 14008 14008 14008 14008 14008 14008 14008 14008 14008
				14008 14008 14008 14008 14008 14008 14008 14008 14008 14008 14008 14008 14008 14008 14008 14008
				14008 14008 14008 14008 14008 14008 14008 14008 14008 14008 14008 14008 14008 14008 14008 14008
				14008 14008 14008 14008 14008 14008 14008 14008 14008 14008 14008 14008 14008 14008 14008 14008
				14008 14008 14008 14008 14008 14008 14008 14008 14008 14008 14008 14008 14008 14008 14008 14008
				14008 14008 14008 14008 14008 14008 14008 14008 14008 14008 14008 14008 14008 14008 14008 14008
				14008 14008 14008 14008 14008 14008 14008 14008 14008 14008 14008 14008 14008 14008 14008 14008
				14008 14008 14008 14008 14008 14008 14008 14008 14008 14008 14008 14008 14008 14008 14008 14008
				14008 14008 14008 14008 14008 14008 14008 14008 14008 14008 14008 14008 14008 14008 14008 14008
				14008 14008 14008 14008 14008 14008 14008 14008 14008 14008 14008 14008 14008 14008 14008 14008
				14008 14008 14008 14008 14008 14008 14008 14008 14008 14008 14008 14008 14008 14008 14008 14008
				14008 14008 14008 14008 14008 14008 14008 14008 14008 14008 14008 14008 14008 14008 14008 14008
				14008 14008 14008 14008 14008 14008 14008 14008 14008 14008 14008 14008 14008 14008 14008 14008
				14008 14008 14008 14008 14008 14008 14008 14008 14008 14008 14008 14008 14008 14008 14008 14008
				14008 14008 14008 14008 14008 14008 14008 14008 14008 14008 14008 14008 14008 14008 14008 14008
				14008 14008 14008 14008 14008 14008 14008 14008 14008 14008 14008 14008 14008 14008 14008 14008
				14008 14008 14008 14008 14008 14008 14008 14008 14008 14008 14008 14008 14008 14008 14008 14008
				14008 14008 14008>;

			PS_Config_Lmt_Short_Rawdata_N = <
				10000 10000 10000 10000 10000 10000 10000 10000 10000 10000 10000 10000 10000 10000 10000 10000
				10000 10000 10000 10000 10000 10000 10000 10000 10000 10000 10000 10000 10000 10000 10000 10000
				10000 10000 10000 10000 10000 10000 10000 10000 10000 10000 10000 10000 10000 10000 10000 10000
				10000 10000 10000 10000 10000 10000 10000 10000 10000 10000 10000 10000 10000 10000 10000 10000
				10000 10000 10000 10000 10000 10000 10000 10000 10000 10000 10000 10000 10000 10000 10000 10000
				10000 10000 10000 10000 10000 10000 10000 10000 10000 10000 10000 10000 10000 10000 10000 10000
				10000 10000 10000 10000 10000 10000 10000 10000 10000 10000 10000 10000 10000 10000 10000 10000
				10000 10000 10000 10000 10000 10000 10000 10000 10000 10000 10000 10000 10000 10000 10000 10000
				10000 10000 10000 10000 10000 10000 10000 10000 10000 10000 10000 10000 10000 10000 10000 10000
				10000 10000 10000 10000 10000 10000 10000 10000 10000 10000 10000 10000 10000 10000 10000 10000
				10000 10000 10000 10000 10000 10000 10000 10000 10000 10000 10000 10000 10000 10000 10000 10000
				10000 10000 10000 10000 10000 10000 10000 10000 10000 10000 10000 10000 10000 10000 10000 10000
				10000 10000 10000 10000 10000 10000 10000 10000 10000 10000 10000 10000 10000 10000 10000 10000
				10000 10000 10000 10000 10000 10000 10000 10000 10000 10000 10000 10000 10000 10000 10000 10000
				10000 10000 10000 10000 10000 10000 10000 10000 10000 10000 10000 10000 10000 10000 10000 10000
				10000 10000 10000 10000 10000 10000 10000 10000 10000 10000 10000 10000 10000 10000 10000 10000
				10000 10000 10000 10000 10000 10000 10000 10000 10000 10000 10000 10000 10000 10000 10000 10000
				10000 10000 10000 10000 10000 10000 10000 10000 10000 10000 10000 10000 10000 10000 10000 10000
				10000 10000 10000 10000 10000 10000 10000 10000 10000 10000 10000 10000 10000 10000 10000 10000
				10000 10000 10000 10000 10000 10000 10000 10000 10000 10000 10000 10000 10000 10000 10000 10000
				10000 10000 10000 10000 10000 10000 10000 10000 10000 10000 10000 10000 10000 10000 10000 10000
				10000 10000 10000 10000 10000 10000 10000 10000 10000 10000 10000 10000 10000 10000 10000 10000
				10000 10000 10000 10000 10000 10000 10000 10000 10000 10000 10000 10000 10000 10000 10000 10000
				10000 10000 10000 10000 10000 10000 10000 10000 10000 10000 10000 10000 10000 10000 10000 10000
				10000 10000 10000 10000 10000 10000 10000 10000 10000 10000 10000 10000 10000 10000 10000 10000
				10000 10000 10000 10000 10000 10000 10000 10000 10000 10000 10000 10000 10000 10000 10000 10000
				10000 10000 10000 10000 10000 10000 10000 10000 10000 10000 10000 10000 10000 10000 10000 10000
				10000 10000 10000 10000 10000 10000 10000 10000 10000 10000 10000 10000 10000 10000 10000 10000
				10000 10000 10000 10000 10000 10000 10000 10000 10000 10000 10000 10000 10000 10000 10000 10000
				10000 10000 10000 10000 10000 10000 10000 10000 10000 10000 10000 10000 10000 10000 10000 10000
				10000 10000 10000 10000 10000 10000 10000 10000 10000 10000 10000 10000 10000 10000 10000 10000
				10000 10000 10000 10000 10000 10000 10000 10000 10000 10000 10000 10000 10000 10000 10000 10000
				10000 10000 10000 10000 10000 10000 10000 10000 10000 10000 10000 10000 10000 10000 10000 10000
				10000 10000 10000 10000 10000 10000 10000 10000 10000 10000 10000 10000 10000 10000 10000 10000
				10000 10000 10000 10000 10000 10000 10000 10000 10000 10000 10000 10000 10000 10000 10000 10000
				10000 10000 10000 10000 10000 10000 10000 10000 10000 10000 10000 10000 10000 10000 10000 10000
				10000 10000 10000>;

			PS_Config_Lmt_Open_Rawdata_P = <
				5120 5120 5120 5120 5120 5120 5120 5120 5120 5120 5120 5120 5120 5120 5120 5120
				5120 5120 5120 5120 5120 5120 5120 5120 5120 5120 5120 5120 5120 5120 5120 5120
				5120 5120 5120 5120 5120 5120 5120 5120 5120 5120 5120 5120 5120 5120 5120 5120
				5120 5120 5120 5120 5120 5120 5120 5120 5120 5120 5120 5120 5120 5120 5120 5120
				5120 5120 5120 5120 5120 5120 5120 5120 5120 5120 5120 5120 5120 5120 5120 5120
				5120 5120 5120 5120 5120 5120 5120 5120 5120 5120 5120 5120 5120 5120 5120 5120
				5120 5120 5120 5120 5120 5120 5120 5120 5120 5120 5120 5120 5120 5120 5120 5120
				5120 5120 5120 5120 5120 5120 5120 5120 5120 5120 5120 5120 5120 5120 5120 5120
				5120 5120 5120 5120 5120 5120 5120 5120 5120 5120 5120 5120 5120 5120 5120 5120
				5120 5120 5120 5120 5120 5120 5120 5120 5120 5120 5120 5120 5120 5120 5120 5120
				5120 5120 5120 5120 5120 5120 5120 5120 5120 5120 5120 5120 5120 5120 5120 5120
				5120 5120 5120 5120 5120 5120 5120 5120 5120 5120 5120 5120 5120 5120 5120 5120
				5120 5120 5120 5120 5120 5120 5120 5120 5120 5120 5120 5120 5120 5120 5120 5120
				5120 5120 5120 5120 5120 5120 5120 5120 5120 5120 5120 5120 5120 5120 5120 5120
				5120 5120 5120 5120 5120 5120 5120 5120 5120 5120 5120 5120 5120 5120 5120 5120
				5120 5120 5120 5120 5120 5120 5120 5120 5120 5120 5120 5120 5120 5120 5120 5120
				5120 5120 5120 5120 5120 5120 5120 5120 5120 5120 5120 5120 5120 5120 5120 5120
				5120 5120 5120 5120 5120 5120 5120 5120 5120 5120 5120 5120 5120 5120 5120 5120
				5120 5120 5120 5120 5120 5120 5120 5120 5120 5120 5120 5120 5120 5120 5120 5120
				5120 5120 5120 5120 5120 5120 5120 5120 5120 5120 5120 5120 5120 5120 5120 5120
				5120 5120 5120 5120 5120 5120 5120 5120 5120 5120 5120 5120 5120 5120 5120 5120
				5120 5120 5120 5120 5120 5120 5120 5120 5120 5120 5120 5120 5120 5120 5120 5120
				5120 5120 5120 5120 5120 5120 5120 5120 5120 5120 5120 5120 5120 5120 5120 5120
				5120 5120 5120 5120 5120 5120 5120 5120 5120 5120 5120 5120 5120 5120 5120 5120
				5120 5120 5120 5120 5120 5120 5120 5120 5120 5120 5120 5120 5120 5120 5120 5120
				5120 5120 5120 5120 5120 5120 5120 5120 5120 5120 5120 5120 5120 5120 5120 5120
				5120 5120 5120 5120 5120 5120 5120 5120 5120 5120 5120 5120 5120 5120 5120 5120
				5120 5120 5120 5120 5120 5120 5120 5120 5120 5120 5120 5120 5120 5120 5120 5120
				5120 5120 5120 5120 5120 5120 5120 5120 5120 5120 5120 5120 5120 5120 5120 5120
				5120 5120 5120 5120 5120 5120 5120 5120 5120 5120 5120 5120 5120 5120 5120 5120
				5120 5120 5120 5120 5120 5120 5120 5120 5120 5120 5120 5120 5120 5120 5120 5120
				5120 5120 5120 5120 5120 5120 5120 5120 5120 5120 5120 5120 5120 5120 5120 5120
				5120 5120 5120 5120 5120 5120 5120 5120 5120 5120 5120 5120 5120 5120 5120 5120
				5120 5120 5120 5120 5120 5120 5120 5120 5120 5120 5120 5120 5120 5120 5120 5120
				5120 5120 5120 5120 5120 5120 5120 5120 5120 5120 5120 5120 5120 5120 5120 5120
				5120 5120 5120 5120 5120 5120 5120 5120 5120 5120 5120 5120 5120 5120 5120 5120
				5120 5120 5120>;

			PS_Config_Lmt_Open_Rawdata_N = <
				(-511) (-511) (-511) (-511) (-511) (-511) (-511) (-511) (-511) (-511) (-511) (-511) (-511) (-511) (-511) (-511)
				(-511) (-511) (-511) (-511) (-511) (-511) (-511) (-511) (-511) (-511) (-511) (-511) (-511) (-511) (-511) (-511)
				(-511) (-511) (-511) (-511) (-511) (-511) (-511) (-511) (-511) (-511) (-511) (-511) (-511) (-511) (-511) (-511)
				(-511) (-511) (-511) (-511) (-511) (-511) (-511) (-511) (-511) (-511) (-511) (-511) (-511) (-511) (-511) (-511)
				(-511) (-511) (-511) (-511) (-511) (-511) (-511) (-511) (-511) (-511) (-511) (-511) (-511) (-511) (-511) (-511)
				(-511) (-511) (-511) (-511) (-511) (-511) (-511) (-511) (-511) (-511) (-511) (-511) (-511) (-511) (-511) (-511)
				(-511) (-511) (-511) (-511) (-511) (-511) (-511) (-511) (-511) (-511) (-511) (-511) (-511) (-511) (-511) (-511)
				(-511) (-511) (-511) (-511) (-511) (-511) (-511) (-511) (-511) (-511) (-511) (-511) (-511) (-511) (-511) (-511)
				(-511) (-511) (-511) (-511) (-511) (-511) (-511) (-511) (-511) (-511) (-511) (-511) (-511) (-511) (-511) (-511)
				(-511) (-511) (-511) (-511) (-511) (-511) (-511) (-511) (-511) (-511) (-511) (-511) (-511) (-511) (-511) (-511)
				(-511) (-511) (-511) (-511) (-511) (-511) (-511) (-511) (-511) (-511) (-511) (-511) (-511) (-511) (-511) (-511)
				(-511) (-511) (-511) (-511) (-511) (-511) (-511) (-511) (-511) (-511) (-511) (-511) (-511) (-511) (-511) (-511)
				(-511) (-511) (-511) (-511) (-511) (-511) (-511) (-511) (-511) (-511) (-511) (-511) (-511) (-511) (-511) (-511)
				(-511) (-511) (-511) (-511) (-511) (-511) (-511) (-511) (-511) (-511) (-511) (-511) (-511) (-511) (-511) (-511)
				(-511) (-511) (-511) (-511) (-511) (-511) (-511) (-511) (-511) (-511) (-511) (-511) (-511) (-511) (-511) (-511)
				(-511) (-511) (-511) (-511) (-511) (-511) (-511) (-511) (-511) (-511) (-511) (-511) (-511) (-511) (-511) (-511)
				(-511) (-511) (-511) (-511) (-511) (-511) (-511) (-511) (-511) (-511) (-511) (-511) (-511) (-511) (-511) (-511)
				(-511) (-511) (-511) (-511) (-511) (-511) (-511) (-511) (-511) (-511) (-511) (-511) (-511) (-511) (-511) (-511)
				(-511) (-511) (-511) (-511) (-511) (-511) (-511) (-511) (-511) (-511) (-511) (-511) (-511) (-511) (-511) (-511)
				(-511) (-511) (-511) (-511) (-511) (-511) (-511) (-511) (-511) (-511) (-511) (-511) (-511) (-511) (-511) (-511)
				(-511) (-511) (-511) (-511) (-511) (-511) (-511) (-511) (-511) (-511) (-511) (-511) (-511) (-511) (-511) (-511)
				(-511) (-511) (-511) (-511) (-511) (-511) (-511) (-511) (-511) (-511) (-511) (-511) (-511) (-511) (-511) (-511)
				(-511) (-511) (-511) (-511) (-511) (-511) (-511) (-511) (-511) (-511) (-511) (-511) (-511) (-511) (-511) (-511)
				(-511) (-511) (-511) (-511) (-511) (-511) (-511) (-511) (-511) (-511) (-511) (-511) (-511) (-511) (-511) (-511)
				(-511) (-511) (-511) (-511) (-511) (-511) (-511) (-511) (-511) (-511) (-511) (-511) (-511) (-511) (-511) (-511)
				(-511) (-511) (-511) (-511) (-511) (-511) (-511) (-511) (-511) (-511) (-511) (-511) (-511) (-511) (-511) (-511)
				(-511) (-511) (-511) (-511) (-511) (-511) (-511) (-511) (-511) (-511) (-511) (-511) (-511) (-511) (-511) (-511)
				(-511) (-511) (-511) (-511) (-511) (-511) (-511) (-511) (-511) (-511) (-511) (-511) (-511) (-511) (-511) (-511)
				(-511) (-511) (-511) (-511) (-511) (-511) (-511) (-511) (-511) (-511) (-511) (-511) (-511) (-511) (-511) (-511)
				(-511) (-511) (-511) (-511) (-511) (-511) (-511) (-511) (-511) (-511) (-511) (-511) (-511) (-511) (-511) (-511)
				(-511) (-511) (-511) (-511) (-511) (-511) (-511) (-511) (-511) (-511) (-511) (-511) (-511) (-511) (-511) (-511)
				(-511) (-511) (-511) (-511) (-511) (-511) (-511) (-511) (-511) (-511) (-511) (-511) (-511) (-511) (-511) (-511)
				(-511) (-511) (-511) (-511) (-511) (-511) (-511) (-511) (-511) (-511) (-511) (-511) (-511) (-511) (-511) (-511)
				(-511) (-511) (-511) (-511) (-511) (-511) (-511) (-511) (-511) (-511) (-511) (-511) (-511) (-511) (-511) (-511)
				(-511) (-511) (-511) (-511) (-511) (-511) (-511) (-511) (-511) (-511) (-511) (-511) (-511) (-511) (-511) (-511)
				(-511) (-511) (-511) (-511) (-511) (-511) (-511) (-511) (-511) (-511) (-511) (-511) (-511) (-511) (-511) (-511)
				(-511) (-511) (-511)>;

			PS_Config_Lmt_FW_Rawdata_P = <
				3840 3840 3840 3840 3840 3840 3840 3840 3840 3840 3840 3840 3840 3840 3840 3840
				3840 3840 3840 3840 3840 3840 3840 3840 3840 3840 3840 3840 3840 3840 3840 3840
				3840 3840 3840 3840 3840 3840 3840 3840 3840 3840 3840 3840 3840 3840 3840 3840
				3840 3840 3840 3840 3840 3840 3840 3840 3840 3840 3840 3840 3840 3840 3840 3840
				3840 3840 3840 3840 3840 3840 3840 3840 3840 3840 3840 3840 3840 3840 3840 3840
				3840 3840 3840 3840 3840 3840 3840 3840 3840 3840 3840 3840 3840 3840 3840 3840
				3840 3840 3840 3840 3840 3840 3840 3840 3840 3840 3840 3840 3840 3840 3840 3840
				3840 3840 3840 3840 3840 3840 3840 3840 3840 3840 3840 3840 3840 3840 3840 3840
				3840 3840 3840 3840 3840 3840 3840 3840 3840 3840 3840 3840 3840 3840 3840 3840
				3840 3840 3840 3840 3840 3840 3840 3840 3840 3840 3840 3840 3840 3840 3840 3840
				3840 3840 3840 3840 3840 3840 3840 3840 3840 3840 3840 3840 3840 3840 3840 3840
				3840 3840 3840 3840 3840 3840 3840 3840 3840 3840 3840 3840 3840 3840 3840 3840
				3840 3840 3840 3840 3840 3840 3840 3840 3840 3840 3840 3840 3840 3840 3840 3840
				3840 3840 3840 3840 3840 3840 3840 3840 3840 3840 3840 3840 3840 3840 3840 3840
				3840 3840 3840 3840 3840 3840 3840 3840 3840 3840 3840 3840 3840 3840 3840 3840
				3840 3840 3840 3840 3840 3840 3840 3840 3840 3840 3840 3840 3840 3840 3840 3840
				3840 3840 3840 3840 3840 3840 3840 3840 3840 3840 3840 3840 3840 3840 3840 3840
				3840 3840 3840 3840 3840 3840 3840 3840 3840 3840 3840 3840 3840 3840 3840 3840
				3840 3840 3840 3840 3840 3840 3840 3840 3840 3840 3840 3840 3840 3840 3840 3840
				3840 3840 3840 3840 3840 3840 3840 3840 3840 3840 3840 3840 3840 3840 3840 3840
				3840 3840 3840 3840 3840 3840 3840 3840 3840 3840 3840 3840 3840 3840 3840 3840
				3840 3840 3840 3840 3840 3840 3840 3840 3840 3840 3840 3840 3840 3840 3840 3840
				3840 3840 3840 3840 3840 3840 3840 3840 3840 3840 3840 3840 3840 3840 3840 3840
				3840 3840 3840 3840 3840 3840 3840 3840 3840 3840 3840 3840 3840 3840 3840 3840
				3840 3840 3840 3840 3840 3840 3840 3840 3840 3840 3840 3840 3840 3840 3840 3840
				3840 3840 3840 3840 3840 3840 3840 3840 3840 3840 3840 3840 3840 3840 3840 3840
				3840 3840 3840 3840 3840 3840 3840 3840 3840 3840 3840 3840 3840 3840 3840 3840
				3840 3840 3840 3840 3840 3840 3840 3840 3840 3840 3840 3840 3840 3840 3840 3840
				3840 3840 3840 3840 3840 3840 3840 3840 3840 3840 3840 3840 3840 3840 3840 3840
				3840 3840 3840 3840 3840 3840 3840 3840 3840 3840 3840 3840 3840 3840 3840 3840
				3840 3840 3840 3840 3840 3840 3840 3840 3840 3840 3840 3840 3840 3840 3840 3840
				3840 3840 3840 3840 3840 3840 3840 3840 3840 3840 3840 3840 3840 3840 3840 3840
				3840 3840 3840 3840 3840 3840 3840 3840 3840 3840 3840 3840 3840 3840 3840 3840
				3840 3840 3840 3840 3840 3840 3840 3840 3840 3840 3840 3840 3840 3840 3840 3840
				3840 3840 3840 3840 3840 3840 3840 3840 3840 3840 3840 3840 3840 3840 3840 3840
				3840 3840 3840 3840 3840 3840 3840 3840 3840 3840 3840 3840 3840 3840 3840 3840
				3840 3840 3840>;

			PS_Config_Lmt_FW_Rawdata_N = <
				240 240 240 240 240 240 240 240 240 240 240 240 240 240 240 240
				240 240 240 240 240 240 240 240 240 240 240 240 240 240 240 240
				240 240 240 240 240 240 240 240 240 240 240 240 240 240 240 240
				240 240 240 240 240 240 240 240 240 240 240 240 240 240 240 240
				240 240 240 240 240 240 240 240 240 240 240 240 240 240 240 240
				240 240 240 240 240 240 240 240 240 240 240 240 240 240 240 240
				240 240 240 240 240 240 240 240 240 240 240 240 240 240 240 240
				240 240 240 240 240 240 240 240 240 240 240 240 240 240 240 240
				240 240 240 240 240 240 240 240 240 240 240 240 240 240 240 240
				240 240 240 240 240 240 240 240 240 240 240 240 240 240 240 240
				240 240 240 240 240 240 240 240 240 240 240 240 240 240 240 240
				240 240 240 240 240 240 240 240 240 240 240 240 240 240 240 240
				240 240 240 240 240 240 240 240 240 240 240 240 240 240 240 240
				240 240 240 240 240 240 240 240 240 240 240 240 240 240 240 240
				240 240 240 240 240 240 240 240 240 240 240 240 240 240 240 240
				240 240 240 240 240 240 240 240 240 240 240 240 240 240 240 240
				240 240 240 240 240 240 240 240 240 240 240 240 240 240 240 240
				240 240 240 240 240 240 240 240 240 240 240 240 240 240 240 240
				240 240 240 240 240 240 240 240 240 240 240 240 240 240 240 240
				240 240 240 240 240 240 240 240 240 240 240 240 240 240 240 240
				240 240 240 240 240 240 240 240 240 240 240 240 240 240 240 240
				240 240 240 240 240 240 240 240 240 240 240 240 240 240 240 240
				240 240 240 240 240 240 240 240 240 240 240 240 240 240 240 240
				240 240 240 240 240 240 240 240 240 240 240 240 240 240 240 240
				240 240 240 240 240 240 240 240 240 240 240 240 240 240 240 240
				240 240 240 240 240 240 240 240 240 240 240 240 240 240 240 240
				240 240 240 240 240 240 240 240 240 240 240 240 240 240 240 240
				240 240 240 240 240 240 240 240 240 240 240 240 240 240 240 240
				240 240 240 240 240 240 240 240 240 240 240 240 240 240 240 240
				240 240 240 240 240 240 240 240 240 240 240 240 240 240 240 240
				240 240 240 240 240 240 240 240 240 240 240 240 240 240 240 240
				240 240 240 240 240 240 240 240 240 240 240 240 240 240 240 240
				240 240 240 240 240 240 240 240 240 240 240 240 240 240 240 240
				240 240 240 240 240 240 240 240 240 240 240 240 240 240 240 240
				240 240 240 240 240 240 240 240 240 240 240 240 240 240 240 240
				240 240 240 240 240 240 240 240 240 240 240 240 240 240 240 240
				240 240 240>;

			PS_Config_Lmt_FW_CC_P = <
				314 314 314 314 314 314 314 314 314 314 314 314 314 314 314 314
				314 314 314 314 314 314 314 314 314 314 314 314 314 314 314 314
				314 314 314 314 314 314 314 314 314 314 314 314 314 314 314 314
				314 314 314 314 314 314 314 314 314 314 314 314 314 314 314 314
				314 314 314 314 314 314 314 314 314 314 314 314 314 314 314 314
				314 314 314 314 314 314 314 314 314 314 314 314 314 314 314 314
				314 314 314 314 314 314 314 314 314 314 314 314 314 314 314 314
				314 314 314 314 314 314 314 314 314 314 314 314 314 314 314 314
				314 314 314 314 314 314 314 314 314 314 314 314 314 314 314 314
				314 314 314 314 314 314 314 314 314 314 314 314 314 314 314 314
				314 314 314 314 314 314 314 314 314 314 314 314 314 314 314 314
				314 314 314 314 314 314 314 314 314 314 314 314 314 314 314 314
				314 314 314 314 314 314 314 314 314 314 314 314 314 314 314 314
				314 314 314 314 314 314 314 314 314 314 314 314 314 314 314 314
				314 314 314 314 314 314 314 314 314 314 314 314 314 314 314 314
				314 314 314 314 314 314 314 314 314 314 314 314 314 314 314 314
				314 314 314 314 314 314 314 314 314 314 314 314 314 314 314 314
				314 314 314 314 314 314 314 314 314 314 314 314 314 314 314 314
				314 314 314 314 314 314 314 314 314 314 314 314 314 314 314 314
				314 314 314 314 314 314 314 314 314 314 314 314 314 314 314 314
				314 314 314 314 314 314 314 314 314 314 314 314 314 314 314 314
				314 314 314 314 314 314 314 314 314 314 314 314 314 314 314 314
				314 314 314 314 314 314 314 314 314 314 314 314 314 314 314 314
				314 314 314 314 314 314 314 314 314 314 314 314 314 314 314 314
				314 314 314 314 314 314 314 314 314 314 314 314 314 314 314 314
				314 314 314 314 314 314 314 314 314 314 314 314 314 314 314 314
				314 314 314 314 314 314 314 314 314 314 314 314 314 314 314 314
				314 314 314 314 314 314 314 314 314 314 314 314 314 314 314 314
				314 314 314 314 314 314 314 314 314 314 314 314 314 314 314 314
				314 314 314 314 314 314 314 314 314 314 314 314 314 314 314 314
				314 314 314 314 314 314 314 314 314 314 314 314 314 314 314 314
				314 314 314 314 314 314 314 314 314 314 314 314 314 314 314 314
				314 314 314 314 314 314 314 314 314 314 314 314 314 314 314 314
				314 314 314 314 314 314 314 314 314 314 314 314 314 314 314 314
				314 314 314 314 314 314 314 314 314 314 314 314 314 314 314 314
				314 314 314 314 314 314 314 314 314 314 314 314 314 314 314 314
				314 314 314>;

			PS_Config_Lmt_FW_CC_N = <
				0 0 0 0 0 0 0 0 0 0 0 0 0 0 0 0
				0 0 0 0 0 0 0 0 0 0 0 0 0 0 0 0
				0 0 0 0 0 0 0 0 0 0 0 0 0 0 0 0
				0 0 0 0 0 0 0 0 0 0 0 0 0 0 0 0
				0 0 0 0 0 0 0 0 0 0 0 0 0 0 0 0
				0 0 0 0 0 0 0 0 0 0 0 0 0 0 0 0
				0 0 0 0 0 0 0 0 0 0 0 0 0 0 0 0
				0 0 0 0 0 0 0 0 0 0 0 0 0 0 0 0
				0 0 0 0 0 0 0 0 0 0 0 0 0 0 0 0
				0 0 0 0 0 0 0 0 0 0 0 0 0 0 0 0
				0 0 0 0 0 0 0 0 0 0 0 0 0 0 0 0
				0 0 0 0 0 0 0 0 0 0 0 0 0 0 0 0
				0 0 0 0 0 0 0 0 0 0 0 0 0 0 0 0
				0 0 0 0 0 0 0 0 0 0 0 0 0 0 0 0
				0 0 0 0 0 0 0 0 0 0 0 0 0 0 0 0
				0 0 0 0 0 0 0 0 0 0 0 0 0 0 0 0
				0 0 0 0 0 0 0 0 0 0 0 0 0 0 0 0
				0 0 0 0 0 0 0 0 0 0 0 0 0 0 0 0
				0 0 0 0 0 0 0 0 0 0 0 0 0 0 0 0
				0 0 0 0 0 0 0 0 0 0 0 0 0 0 0 0
				0 0 0 0 0 0 0 0 0 0 0 0 0 0 0 0
				0 0 0 0 0 0 0 0 0 0 0 0 0 0 0 0
				0 0 0 0 0 0 0 0 0 0 0 0 0 0 0 0
				0 0 0 0 0 0 0 0 0 0 0 0 0 0 0 0
				0 0 0 0 0 0 0 0 0 0 0 0 0 0 0 0
				0 0 0 0 0 0 0 0 0 0 0 0 0 0 0 0
				0 0 0 0 0 0 0 0 0 0 0 0 0 0 0 0
				0 0 0 0 0 0 0 0 0 0 0 0 0 0 0 0
				0 0 0 0 0 0 0 0 0 0 0 0 0 0 0 0
				0 0 0 0 0 0 0 0 0 0 0 0 0 0 0 0
				0 0 0 0 0 0 0 0 0 0 0 0 0 0 0 0
				0 0 0 0 0 0 0 0 0 0 0 0 0 0 0 0
				0 0 0 0 0 0 0 0 0 0 0 0 0 0 0 0
				0 0 0 0 0 0 0 0 0 0 0 0 0 0 0 0
				0 0 0 0 0 0 0 0 0 0 0 0 0 0 0 0
				0 0 0 0 0 0 0 0 0 0 0 0 0 0 0 0
				0 0 0>;

			PS_Config_Lmt_FW_Diff_P = <
				75 75 75 75 75 75 75 75 75 75 75 75 75 75 75 75
				75 75 75 75 75 75 75 75 75 75 75 75 75 75 75 75
				75 75 75 75 75 75 75 75 75 75 75 75 75 75 75 75
				75 75 75 75 75 75 75 75 75 75 75 75 75 75 75 75
				75 75 75 75 75 75 75 75 75 75 75 75 75 75 75 75
				75 75 75 75 75 75 75 75 75 75 75 75 75 75 75 75
				75 75 75 75 75 75 75 75 75 75 75 75 75 75 75 75
				75 75 75 75 75 75 75 75 75 75 75 75 75 75 75 75
				75 75 75 75 75 75 75 75 75 75 75 75 75 75 75 75
				75 75 75 75 75 75 75 75 75 75 75 75 75 75 75 75
				75 75 75 75 75 75 75 75 75 75 75 75 75 75 75 75
				75 75 75 75 75 75 75 75 75 75 75 75 75 75 75 75
				75 75 75 75 75 75 75 75 75 75 75 75 75 75 75 75
				75 75 75 75 75 75 75 75 75 75 75 75 75 75 75 75
				75 75 75 75 75 75 75 75 75 75 75 75 75 75 75 75
				75 75 75 75 75 75 75 75 75 75 75 75 75 75 75 75
				75 75 75 75 75 75 75 75 75 75 75 75 75 75 75 75
				75 75 75 75 75 75 75 75 75 75 75 75 75 75 75 75
				75 75 75 75 75 75 75 75 75 75 75 75 75 75 75 75
				75 75 75 75 75 75 75 75 75 75 75 75 75 75 75 75
				75 75 75 75 75 75 75 75 75 75 75 75 75 75 75 75
				75 75 75 75 75 75 75 75 75 75 75 75 75 75 75 75
				75 75 75 75 75 75 75 75 75 75 75 75 75 75 75 75
				75 75 75 75 75 75 75 75 75 75 75 75 75 75 75 75
				75 75 75 75 75 75 75 75 75 75 75 75 75 75 75 75
				75 75 75 75 75 75 75 75 75 75 75 75 75 75 75 75
				75 75 75 75 75 75 75 75 75 75 75 75 75 75 75 75
				75 75 75 75 75 75 75 75 75 75 75 75 75 75 75 75
				75 75 75 75 75 75 75 75 75 75 75 75 75 75 75 75
				75 75 75 75 75 75 75 75 75 75 75 75 75 75 75 75
				75 75 75 75 75 75 75 75 75 75 75 75 75 75 75 75
				75 75 75 75 75 75 75 75 75 75 75 75 75 75 75 75
				75 75 75 75 75 75 75 75 75 75 75 75 75 75 75 75
				75 75 75 75 75 75 75 75 75 75 75 75 75 75 75 75
				75 75 75 75 75 75 75 75 75 75 75 75 75 75 75 75
				75 75 75 75 75 75 75 75 75 75 75 75 75 75 75 75
				75 75 75>;

			PS_Config_Lmt_FW_Diff_N = <
				(-75) (-75) (-75) (-75) (-75) (-75) (-75) (-75) (-75) (-75) (-75) (-75) (-75) (-75) (-75) (-75)
				(-75) (-75) (-75) (-75) (-75) (-75) (-75) (-75) (-75) (-75) (-75) (-75) (-75) (-75) (-75) (-75)
				(-75) (-75) (-75) (-75) (-75) (-75) (-75) (-75) (-75) (-75) (-75) (-75) (-75) (-75) (-75) (-75)
				(-75) (-75) (-75) (-75) (-75) (-75) (-75) (-75) (-75) (-75) (-75) (-75) (-75) (-75) (-75) (-75)
				(-75) (-75) (-75) (-75) (-75) (-75) (-75) (-75) (-75) (-75) (-75) (-75) (-75) (-75) (-75) (-75)
				(-75) (-75) (-75) (-75) (-75) (-75) (-75) (-75) (-75) (-75) (-75) (-75) (-75) (-75) (-75) (-75)
				(-75) (-75) (-75) (-75) (-75) (-75) (-75) (-75) (-75) (-75) (-75) (-75) (-75) (-75) (-75) (-75)
				(-75) (-75) (-75) (-75) (-75) (-75) (-75) (-75) (-75) (-75) (-75) (-75) (-75) (-75) (-75) (-75)
				(-75) (-75) (-75) (-75) (-75) (-75) (-75) (-75) (-75) (-75) (-75) (-75) (-75) (-75) (-75) (-75)
				(-75) (-75) (-75) (-75) (-75) (-75) (-75) (-75) (-75) (-75) (-75) (-75) (-75) (-75) (-75) (-75)
				(-75) (-75) (-75) (-75) (-75) (-75) (-75) (-75) (-75) (-75) (-75) (-75) (-75) (-75) (-75) (-75)
				(-75) (-75) (-75) (-75) (-75) (-75) (-75) (-75) (-75) (-75) (-75) (-75) (-75) (-75) (-75) (-75)
				(-75) (-75) (-75) (-75) (-75) (-75) (-75) (-75) (-75) (-75) (-75) (-75) (-75) (-75) (-75) (-75)
				(-75) (-75) (-75) (-75) (-75) (-75) (-75) (-75) (-75) (-75) (-75) (-75) (-75) (-75) (-75) (-75)
				(-75) (-75) (-75) (-75) (-75) (-75) (-75) (-75) (-75) (-75) (-75) (-75) (-75) (-75) (-75) (-75)
				(-75) (-75) (-75) (-75) (-75) (-75) (-75) (-75) (-75) (-75) (-75) (-75) (-75) (-75) (-75) (-75)
				(-75) (-75) (-75) (-75) (-75) (-75) (-75) (-75) (-75) (-75) (-75) (-75) (-75) (-75) (-75) (-75)
				(-75) (-75) (-75) (-75) (-75) (-75) (-75) (-75) (-75) (-75) (-75) (-75) (-75) (-75) (-75) (-75)
				(-75) (-75) (-75) (-75) (-75) (-75) (-75) (-75) (-75) (-75) (-75) (-75) (-75) (-75) (-75) (-75)
				(-75) (-75) (-75) (-75) (-75) (-75) (-75) (-75) (-75) (-75) (-75) (-75) (-75) (-75) (-75) (-75)
				(-75) (-75) (-75) (-75) (-75) (-75) (-75) (-75) (-75) (-75) (-75) (-75) (-75) (-75) (-75) (-75)
				(-75) (-75) (-75) (-75) (-75) (-75) (-75) (-75) (-75) (-75) (-75) (-75) (-75) (-75) (-75) (-75)
				(-75) (-75) (-75) (-75) (-75) (-75) (-75) (-75) (-75) (-75) (-75) (-75) (-75) (-75) (-75) (-75)
				(-75) (-75) (-75) (-75) (-75) (-75) (-75) (-75) (-75) (-75) (-75) (-75) (-75) (-75) (-75) (-75)
				(-75) (-75) (-75) (-75) (-75) (-75) (-75) (-75) (-75) (-75) (-75) (-75) (-75) (-75) (-75) (-75)
				(-75) (-75) (-75) (-75) (-75) (-75) (-75) (-75) (-75) (-75) (-75) (-75) (-75) (-75) (-75) (-75)
				(-75) (-75) (-75) (-75) (-75) (-75) (-75) (-75) (-75) (-75) (-75) (-75) (-75) (-75) (-75) (-75)
				(-75) (-75) (-75) (-75) (-75) (-75) (-75) (-75) (-75) (-75) (-75) (-75) (-75) (-75) (-75) (-75)
				(-75) (-75) (-75) (-75) (-75) (-75) (-75) (-75) (-75) (-75) (-75) (-75) (-75) (-75) (-75) (-75)
				(-75) (-75) (-75) (-75) (-75) (-75) (-75) (-75) (-75) (-75) (-75) (-75) (-75) (-75) (-75) (-75)
				(-75) (-75) (-75) (-75) (-75) (-75) (-75) (-75) (-75) (-75) (-75) (-75) (-75) (-75) (-75) (-75)
				(-75) (-75) (-75) (-75) (-75) (-75) (-75) (-75) (-75) (-75) (-75) (-75) (-75) (-75) (-75) (-75)
				(-75) (-75) (-75) (-75) (-75) (-75) (-75) (-75) (-75) (-75) (-75) (-75) (-75) (-75) (-75) (-75)
				(-75) (-75) (-75) (-75) (-75) (-75) (-75) (-75) (-75) (-75) (-75) (-75) (-75) (-75) (-75) (-75)
				(-75) (-75) (-75) (-75) (-75) (-75) (-75) (-75) (-75) (-75) (-75) (-75) (-75) (-75) (-75) (-75)
				(-75) (-75) (-75) (-75) (-75) (-75) (-75) (-75) (-75) (-75) (-75) (-75) (-75) (-75) (-75) (-75)
				(-75) (-75) (-75)>;

			PS_Config_Diff_Test_Frame = <50>;
		};
	};
};

&qupv3_se9_i2c {
	status = "ok";
	nq@28 {
		compatible = "qcom,nq-nci";
		reg = <0x28>;
		qcom,nq-irq = <&tlmm 47 0x00>;
		qcom,nq-ven = <&tlmm 102 0x00>;
		qcom,nq-firm = <&tlmm 48 0x00>;
		qcom,nq-clkreq = <&tlmm 113 0x00>;
		//qcom,nq-esepwr = <&tlmm 42 0x00>;
		interrupt-parent = <&tlmm>;
		interrupts = <47 0>;
		interrupt-names = "nfc_irq";
		pinctrl-names = "nfc_active", "nfc_suspend";
		pinctrl-0 = <&nfc_int_active &nfc_enable_active
					&nfc_clk_req_active>;
		pinctrl-1 = <&nfc_int_suspend &nfc_enable_suspend
					&nfc_clk_req_suspend>;
	};
};

&qupv3_se1_spi {
	status = "ok";
	irled@0 {
		compatible = "ir-spi";
		reg = <0x0>;
		status = "ok";
		spi-max-frequency = <19200000>;
	};
};

&pm8150l_lpg {
	qcom,lut-patterns = <0 1 2 3 4 5 7 9 11 13 15
				13 11 9 7 5 4 3 2 1 0>;
};

&pwm_lpg1 {
	qcom,lpg-chan-id = <1>;
	qcom,ramp-step-ms = <100>;
	qcom,ramp-pause-hi-count = <2>;
	qcom,ramp-pause-lo-count = <2>;
	qcom,ramp-low-index = <0>;
	qcom,ramp-high-index = <20>;
	qcom,ramp-from-low-to-high;
	qcom,ramp-pattern-repeat;
};

&red_led {
	label = "white";
};

&green_led {
	status = "disabled";
};

&blue_led {
	status = "disabled";
};

&mdss_mdp {
       clock-rate = <0 0 0 0 345000000 19200000 300000000 19200000>;
};


&sde_dsi {
	vcie-supply = <&disp_vci_vreg>;
};

&dsi_j20s_36_02_0a_video {
	qcom,panel-supply-entries = <&dsi_panel_pwr_supply>;
};

&dsi_j20s_42_02_0b_video {
	qcom,panel-supply-entries = <&dsi_panel_pwr_supply>;
};

&pm8150l_wled {
	status = "okay";
	qcom,string-cfg = <7>;
	qcom,ovp = <28000>;
	qcom,fs-current-limit = <22500>;
	qcom,cabc-sel = <1>;
};


&pm8150b_vadc {
	vph_pwr {
		reg = <ADC_VPH_PWR>;
		label = "vph_pwr";
		qcom,pre-scaling = <1 3>;
	};

	wp_therm {
		reg = <ADC_AMUX_THM1_PU2>;
		label = "wp_therm";
		qcom,ratiometric;
		qcom,hw-settle-time = <200>;
		qcom,pre-scaling = <1 1>;
	};

	vcoin {
		reg = <ADC_VCOIN>;
		label = "vcoin";
		qcom,pre-scaling = <1 3>;
	};

	conn_therm {
		reg = <ADC_AMUX_THM3_PU2>;
		label = "conn_therm";
		qcom,ratiometric;
		qcom,hw-settle-time = <200>;
		qcom,pre-scaling = <1 1>;
	};

	chg_sbux {
		reg = <ADC_SBUx>;
		label = "chg_sbux";
		qcom,pre-scaling = <1 3>;
	};

	mid_chg_div6 {
		reg = <ADC_MID_CHG_DIV6>;
		label = "chg_mid";
		qcom,pre-scaling = <1 6>;
	};

	usb_in_i_uv {
		reg = <ADC_USB_IN_I>;
		label = "usb_in_i_uv";
		qcom,pre-scaling = <1 1>;
	};

	usb_in_v_div_16 {
		reg = <ADC_USB_IN_V_16>;
		label = "usb_in_v_div_16";
		qcom,pre-scaling = <1 16>;
	};
};

&pm8150_vadc {
	vph_pwr {
		reg = <ADC_VPH_PWR>;
		label = "vph_pwr";
		qcom,pre-scaling = <1 3>;
	};

	vcoin {
		reg = <ADC_VCOIN>;
		label = "vcoin";
		qcom,pre-scaling = <1 3>;
	};

	xo_therm {
		reg = <ADC_XO_THERM_PU2>;
		label = "xo_therm";
		qcom,ratiometric;
		qcom,hw-settle-time = <200>;
		qcom,pre-scaling = <1 1>;
	};

	quiet_therm {
		reg = <ADC_AMUX_THM1_PU2>;
		label = "quiet_therm";
		qcom,ratiometric;
		qcom,hw-settle-time = <200>;
		qcom,pre-scaling = <1 1>;
	};

	pa_therm0 {
		reg = <ADC_AMUX_THM2_PU2>;
		label = "pa_therm0";
		qcom,ratiometric;
		qcom,hw-settle-time = <200>;
		qcom,pre-scaling = <1 1>;
	};
};

&pm8150l_vadc {
	vph_pwr {
		reg = <ADC_VPH_PWR>;
		label = "vph_pwr";
		qcom,pre-scaling = <1 3>;
	};

	cam_therm0 {
		reg = <ADC_AMUX_THM1_PU2>;
		label = "cam_therm0";
		qcom,ratiometric;
		qcom,hw-settle-time = <200>;
		qcom,pre-scaling = <1 1>;
	};

	cam_therm1 {
		reg = <ADC_AMUX_THM2_PU2>;
		label = "cam_therm1";
		qcom,ratiometric;
		qcom,hw-settle-time = <200>;
		qcom,pre-scaling = <1 1>;
	};

	pa_therm1 {
		reg = <ADC_AMUX_THM3_PU2>;
		label = "pa_therm1";
		qcom,ratiometric;
		qcom,hw-settle-time = <200>;
		qcom,pre-scaling = <1 1>;
	};
};

&pm8150b_adc_tm {
	wp_therm {
		reg = <ADC_AMUX_THM1_PU2>;
		qcom,ratiometric;
		qcom,hw-settle-time = <200>;
	};
};

&pm8150_adc_tm {
	xo_therm {
		reg = <ADC_XO_THERM_PU2>;
		qcom,ratiometric;
		qcom,hw-settle-time = <200>;
	};
        quiet_therm {
                reg = <ADC_AMUX_THM1_PU2>;
                qcom,ratiometric;
                qcom,hw-settle-time = <200>;
        };

        pa_therm0 {
                reg = <ADC_AMUX_THM2_PU2>;
                qcom,ratiometric;
                qcom,hw-settle-time = <200>;
        };
};

&pm8150l_adc_tm {
	cam_therm0 {
		reg = <ADC_AMUX_THM1_PU2>;
		qcom,ratiometric;
		qcom,hw-settle-time = <200>;
	};

	cam_therm1 {
		reg = <ADC_AMUX_THM2_PU2>;
		qcom,ratiometric;
		qcom,hw-settle-time = <200>;
	};

	pa_therm1 {
		reg = <ADC_AMUX_THM3_PU2>;
		qcom,ratiometric;
		qcom,hw-settle-time = <200>;
	};
};

&thermal_zones {
	wp_therm {
		polling-delay-passive = <0>;
		polling-delay = <0>;
		thermal-governor = "user_space";
		thermal-sensors = <&pm8150b_adc_tm ADC_AMUX_THM1_PU2>;
		trips {
			active-config0 {
				temperature = <125000>;
				hysteresis = <1000>;
				type = "passive";
			};
		};
	};

	xo_therm {
		polling-delay-passive = <0>;
		polling-delay = <0>;
		thermal-governor = "user_space";
		thermal-sensors = <&pm8150_adc_tm ADC_XO_THERM_PU2>;
		trips {
			active-config0 {
				temperature = <125000>;
				hysteresis = <1000>;
				type = "passive";
			};
		};
	};

        quiet_therm {
                polling-delay-passive = <0>;
                polling-delay = <0>;
                thermal-governor = "user_space";
                thermal-sensors = <&pm8150_adc_tm ADC_AMUX_THM1_PU2>;
                trips {
                       active-config0 {
                               temperature = <125000>;
                               hysteresis = <1000>;
                               type = "passive";
                       };
                };
        };

        pa_therm0 {
                polling-delay-passive = <0>;
                polling-delay = <0>;
                thermal-governor = "user_space";
                thermal-sensors = <&pm8150_adc_tm ADC_AMUX_THM2_PU2>;
                trips {
                       active-config0 {
                               temperature = <125000>;
                               hysteresis = <1000>;
                               type = "passive";
                       };
                };
        };

	cam_therm0 {
		polling-delay-passive = <0>;
		polling-delay = <0>;
		thermal-governor = "user_space";
		thermal-sensors = <&pm8150l_adc_tm ADC_AMUX_THM1_PU2>;
		trips {
			active-config0 {
				temperature = <125000>;
				hysteresis = <1000>;
				type = "passive";
			};
		};
	};

	cam_therm1 {
		polling-delay-passive = <0>;
		polling-delay = <0>;
		thermal-governor = "user_space";
		thermal-sensors = <&pm8150l_adc_tm ADC_AMUX_THM2_PU2>;
		trips {
			active-config0 {
				temperature = <125000>;
				hysteresis = <1000>;
				type = "passive";
			};
		};
	};

	pa_therm1 {
		polling-delay-passive = <0>;
		polling-delay = <0>;
		thermal-governor = "user_space";
		thermal-sensors = <&pm8150l_adc_tm ADC_AMUX_THM3_PU2>;
		trips {
			active-config0 {
				temperature = <125000>;
				hysteresis = <1000>;
				type = "passive";
			};
		};
	};
};

&pm8150b_haptics {
	qcom,vmax-mv = <2800>;
	qcom,play-rate-us = <5102>;

	wf_0 {
		/* CLICK */
		qcom,wf-vmax-mv = <3600>;
		qcom,wf-pattern = [3e 3e];
		qcom,wf-brake-pattern = [02 01 00 00];
		qcom,wf-play-rate-us = <5102>;
	};
	wf_1 {
		/* DOUBLE CLICK */
		qcom,wf-vmax-mv = <3600>;
		qcom,wf-pattern = [7e 3e];
		qcom,wf-brake-pattern = [03 01 01 00];
		qcom,wf-play-rate-us = <5102>;
	};
	wf_2 {
		/* TICK */
		qcom,wf-vmax-mv = <3600>;
		qcom,wf-pattern = [7e 3e];
		qcom,wf-brake-pattern = [03 01 01 00];
		qcom,wf-play-rate-us = <5102>;
	};
	wf_3 {
		/* THUD */
		qcom,wf-vmax-mv = <3600>;
		qcom,wf-pattern = [3e 3e];
		qcom,wf-brake-pattern = [02 01 00 00];
		qcom,wf-play-rate-us = <5102>;
	};
	wf_4 {
		/* POP */
		qcom,wf-vmax-mv = <3600>;
		qcom,wf-pattern = [3e 3e];
		qcom,wf-brake-pattern = [02 01 00 00];
		qcom,wf-play-rate-us = <5102>;
	};
	wf_5 {
		/* HEAVY CLICK */
		qcom,wf-vmax-mv = <3600>;
		qcom,wf-pattern = [7e 7e 7e];
		qcom,wf-brake-pattern = [03 03 01 00];
		qcom,wf-play-rate-us = <5102>;
	};
};

&soc {
	ssc_sensors: qcom,msm-ssc-sensors {
		compatible = "qcom,msm-ssc-sensors";
		status = "ok";
		qcom,firmware-name = "slpi_vy";
	};

	thermal_message: thermal-message {
		board-sensor = "quiet_therm";
	};
};

&sdhc_2 {
	cd-gpios = <&tlmm 96 GPIO_ACTIVE_HIGH>;
	status = "ok";
 };

&tlmm {
        /* GPIO_37 : FP_RESET_N */
        msm_gpio_37: msm_gpio_37 {
                mux {
                         pins = "gpio37";
                         function = "gpio";
                };

                config {
                        pins = "gpio37";
                        drive-strength = <2>;
                        bias-disable;
                        output-low;
                };
        };

        /* GPIO_37 : FP_RESET_N, state device active*/
        msm_gpio_37_output_high: msm_gpio_37_output_high {
                mux {
                        pins = "gpio37";
                        function = "gpio";
                };

                config {
                        pins = "gpio37";
                        drive-strength = <2>;
                        bias-disable;
                        output-high;
                };
        };

        /* GPIO_120 : FP_INT_N */
        msm_gpio_120: msm_gpio_120 {
                mux {
                        pins = "gpio120";
                        function = "gpio";
                };

                config {
                        pins = "gpio120";
                        drive-strength = <2>;
                        bias-pull-down;
                };
        };
};

